AUTOSAR XML (schema 4-1-3)
standard types defined: boolean, sint8, uint16, uint32, uint8, boolean_CompuMethod, boolean_DataConstr, sint8_DataConstr, uint16_DataConstr, uint32_DataConstr, uint8_DataConstr, sint16
package /ComponentTypes
  swc implementation Implementation_HvacDampr_Ctrl: behavior=HvacDampr_Ctrl_InternalBehavior
    code-descriptors:
      code Default: artifact-descriptors=autosar-engineering-object={short-label=Default, category=SWSRC}
package /IoHwAb/Interface
  client server interface IoHwAb_IoDiagHbr
    operation Hbr_Get: possible-error=IoHwAb_IoDiagHbr/E_NOT_OK
      arg id_u16: type=ImplementationDataTypes/uint16, direction=IN, server-argument-impl-policy=USE-ARGUMENT-TYPE
      arg val_u32: type=uint32, direction=OUT, server-argument-impl-policy=USE-ARGUMENT-TYPE
    error E_NOT_OK: error-code=1
package /MICROSAR/Dem_swc/DataTypes
  5 x impl type:
    Dem_DebounceResetStatusType: compu {0=DEM_DEBOUNCE_STATUS_FREEZE, 1=DEM_DEBOUNCE_STATUS_RESET}, range raw 0..255, implementation-data-type=ImplementationDataTypes/uint8
    Dem_DTCFormatType: compu {0=DEM_DTC_FORMAT_OBD, 1=DEM_DTC_FORMAT_UDS, 2=DEM_DTC_FORMAT_J1939}, range raw 0..2, implementation-data-type=ImplementationDataTypes/uint8
    Dem_EventStatusType:
      compu {0=DEM_EVENT_STATUS_PASSED, 1=DEM_EVENT_STATUS_FAILED, 2=DEM_EVENT_STATUS_PREPASSED, 3=DEM_EVENT_STATUS_PREFAILED, 4=DEM_EVENT_STATUS_FDC_THRESHOLD_REACHED, 5=DEM_EVENT_STATUS_PASSED_CONDITIONS_NOT_FULFILLED, 6=DEM_EVENT_STATUS_FAILED_CONDITIONS_NOT_FULFILLED, 7=DEM_EVENT_STATUS_PREPASSED_CONDITIONS_NOT_FULFILLED, 8=DEM_EVENT_STATUS_PREFAILED_CONDITIONS_NOT_FULFILLED}
      range raw 0..255
      implementation-data-type=ImplementationDataTypes/uint8
    Dem_MaxDataValueType: category=ARRAY, sw-calibration-access=READ-ONLY
      element Dem_MaxDataValueTypeElement: array-size=40, array-size-semantics=FIXED-SIZE, implementation-data-type=ImplementationDataTypes/uint8
    Dem_UdsStatusByteType:
      compu {mask 1: 1=DEM_UDS_STATUS_TF (bit 0: TestFailed), mask 2: 2=DEM_UDS_STATUS_TFTOC (bit 1: TestFailedThisOperationCycle), mask 4: 4=DEM_UDS_STATUS_PDTC (bit 2: PendingDTC), mask 8: 8=DEM_UDS_STATUS_CDTC (bit 3: ConfirmedDTC), mask 16: 16=DEM_UDS_STATUS_TNCSLC (bit 4: TestNotCompletedSinceLastClear), mask 32: 32=DEM_UDS_STATUS_TFSLC (bit 5: TestFailedSinceLastClear), mask 64: 64=DEM_UDS_STATUS_TNCTOC (bit 6: TestNotCompletedThisOperationCycle), mask 128: 128=DEM_UDS_STATUS_WIR (bit 7: WarningIndicatorRequested)}
      range raw 0..255
      implementation-data-type=ImplementationDataTypes/uint8
package /MICROSAR/Dem_swc/Interfaces
  client server interface DiagnosticMonitor: is-service=true, service-kind=DIAGNOSTIC-EVENT-MANAGER
    11 x operation:
      GetDTCOfEvent: possible-error=[DEM_E_NO_DTC_AVAILABLE, DiagnosticMonitor/E_NOT_OK]
        arg DTCFormat: type=Dem_DTCFormatType, direction=IN, server-argument-impl-policy=USE-ARGUMENT-TYPE
        arg DTCOfEvent: type=uint32, direction=OUT, server-argument-impl-policy=USE-ARGUMENT-TYPE
      GetEventExtendedDataRecordEx: possible-error=[DEM_BUFFER_TOO_SMALL, DEM_NO_SUCH_ELEMENT, DiagnosticMonitor/E_NOT_OK]
        arg RecordNumber: type=ImplementationDataTypes/uint8, direction=IN, server-argument-impl-policy=USE-ARGUMENT-TYPE
        arg DestBuffer: type=Dem_MaxDataValueType, direction=OUT, server-argument-impl-policy=USE-ARGUMENT-TYPE
        arg BufSize: type=ImplementationDataTypes/uint16, direction=INOUT, server-argument-impl-policy=USE-ARGUMENT-TYPE
      GetEventFailed: possible-error=DiagnosticMonitor/E_NOT_OK
        arg EventFailed: type=ImplementationDataTypes/boolean, direction=OUT, server-argument-impl-policy=USE-ARGUMENT-TYPE
      GetEventFreezeFrameDataEx: possible-error=[DEM_BUFFER_TOO_SMALL, DEM_NO_SUCH_ELEMENT, DiagnosticMonitor/E_NOT_OK]
        4 x arg, all with server-argument-impl-policy=USE-ARGUMENT-TYPE:
          RecordNumber: type=ImplementationDataTypes/uint8, direction=IN
          DataId: type=ImplementationDataTypes/uint16, direction=IN
          DestBuffer: type=Dem_MaxDataValueType, direction=OUT
          BufSize: type=ImplementationDataTypes/uint16, direction=INOUT
      GetEventStatus: possible-error=DiagnosticMonitor/E_NOT_OK
        arg UDSStatusByte: type=Dem_UdsStatusByteType, direction=OUT, server-argument-impl-policy=USE-ARGUMENT-TYPE
      GetEventTested: possible-error=DiagnosticMonitor/E_NOT_OK
        arg EventTested: type=ImplementationDataTypes/boolean, direction=OUT, server-argument-impl-policy=USE-ARGUMENT-TYPE
      GetEventUdsStatus: possible-error=DiagnosticMonitor/E_NOT_OK
        arg UDSStatusByte: type=Dem_UdsStatusByteType, direction=OUT, server-argument-impl-policy=USE-ARGUMENT-TYPE
      GetFaultDetectionCounter: possible-error=[DEM_E_NO_FDC_AVAILABLE, DiagnosticMonitor/E_NOT_OK]
        arg FaultDetectionCounter: type=sint8, direction=OUT, server-argument-impl-policy=USE-ARGUMENT-TYPE
      ResetEventDebounceStatus: possible-error=DiagnosticMonitor/E_NOT_OK
        arg DebounceResetStatus: type=Dem_DebounceResetStatusType, direction=IN, server-argument-impl-policy=USE-ARGUMENT-TYPE
      ResetEventStatus: possible-error=DiagnosticMonitor/E_NOT_OK
      SetEventStatus: possible-error=DiagnosticMonitor/E_NOT_OK
        arg EventStatus: type=Dem_EventStatusType, direction=IN, server-argument-impl-policy=USE-ARGUMENT-TYPE
    5 x error:
      DEM_BUFFER_TOO_SMALL: error-code=21
      DEM_E_NO_DTC_AVAILABLE: error-code=10
      DEM_E_NO_FDC_AVAILABLE: error-code=14
      DEM_NO_SUCH_ELEMENT: error-code=48
      E_NOT_OK: error-code=1
package /UAES/ASW/ApplicationDataTypes
  25 x app type, all with sw-calibration-access=READ-WRITE:
    Appl_HVAC_CRCHmixToPosCnv_CUR: category=CURVE, sw-calprm-axis-set={sw-axis-index=1, category=COM_AXIS, sw-axis-individual={compu {identical}, sw-max-axis-points=2, sw-min-axis-points=2, range raw 0..255}}, compu {identical}, range raw 0..65535
    Appl_HVAC_CRCHmixToPosCnv_CUR2: category=CURVE, sw-calprm-axis-set={sw-axis-index=1, category=COM_AXIS, sw-axis-individual={compu {identical}, sw-max-axis-points=2, sw-min-axis-points=2, range raw 0..255}}, compu {identical}, range raw 0..65535
    Appl_HVAC_CRCHmixToPosCnv_CUR3: category=CURVE, sw-calprm-axis-set={sw-axis-index=1, category=COM_AXIS, sw-axis-individual={compu {identical}, sw-max-axis-points=2, sw-min-axis-points=2, range raw 0..255}}, compu {identical}, range raw 0..65535
    Appl_HVAC_CRCPosToHmixCnv_CUR: category=CURVE, sw-calprm-axis-set={sw-axis-index=1, category=COM_AXIS, sw-axis-individual={compu {identical}, sw-max-axis-points=2, sw-min-axis-points=2, range raw 0..65535}}, compu {identical}, range raw 0..255
    Appl_HVAC_CRCPosToHmixCnv_CUR2: category=CURVE, sw-calprm-axis-set={sw-axis-index=1, category=COM_AXIS, sw-axis-individual={compu {identical}, sw-max-axis-points=2, sw-min-axis-points=2, range raw 0..65535}}, compu {identical}, range raw 0..255
    Appl_HVAC_CRCPosToHmixCnv_CUR3: category=CURVE, sw-calprm-axis-set={sw-axis-index=1, category=COM_AXIS, sw-axis-individual={compu {identical}, sw-max-axis-points=2, sw-min-axis-points=2, range raw 0..65535}}, compu {identical}, range raw 0..255
    Appl_HVAC_DrTempHmixToPosCnv_CUR: category=CURVE, sw-calprm-axis-set={sw-axis-index=1, category=COM_AXIS, sw-axis-individual={compu {identical}, sw-max-axis-points=2, sw-min-axis-points=2, range raw 0..65535}}, compu {identical}, range raw 0..65535
    Appl_HVAC_DrTempHmixToPosCnv_CUR2: category=CURVE, sw-calprm-axis-set={sw-axis-index=1, category=COM_AXIS, sw-axis-individual={compu {identical}, sw-max-axis-points=2, sw-min-axis-points=2, range raw 0..65535}}, compu {identical}, range raw 0..65535
    Appl_HVAC_DrTempHmixToPosCnv_CUR3: category=CURVE, sw-calprm-axis-set={sw-axis-index=1, category=COM_AXIS, sw-axis-individual={compu {identical}, sw-max-axis-points=2, sw-min-axis-points=2, range raw 0..65535}}, compu {identical}, range raw 0..65535
    Appl_HVAC_DrTempPosToHmixCnv_CUR: category=CURVE, sw-calprm-axis-set={sw-axis-index=1, category=COM_AXIS, sw-axis-individual={compu {identical}, sw-max-axis-points=2, sw-min-axis-points=2, range raw 0..65535}}, compu {identical}, range raw 0..65535
    Appl_HVAC_DrTempPosToHmixCnv_CUR2: category=CURVE, sw-calprm-axis-set={sw-axis-index=1, category=COM_AXIS, sw-axis-individual={compu {identical}, sw-max-axis-points=2, sw-min-axis-points=2, range raw 0..65535}}, compu {identical}, range raw 0..65535
    Appl_HVAC_DrTempPosToHmixCnv_CUR3: category=CURVE, sw-calprm-axis-set={sw-axis-index=1, category=COM_AXIS, sw-axis-individual={compu {identical}, sw-max-axis-points=2, sw-min-axis-points=2, range raw 0..65535}}, compu {identical}, range raw 0..65535
    Appl_HVAC_PaTempHmixToPosCnv_CUR: category=CURVE, sw-calprm-axis-set={sw-axis-index=1, category=COM_AXIS, sw-axis-individual={compu {identical}, sw-max-axis-points=2, sw-min-axis-points=2, range raw 0..65535}}, compu {identical}, range raw 0..65535
    Appl_HVAC_PaTempHmixToPosCnv_CUR2: category=CURVE, sw-calprm-axis-set={sw-axis-index=1, category=COM_AXIS, sw-axis-individual={compu {identical}, sw-max-axis-points=2, sw-min-axis-points=2, range raw 0..65535}}, compu {identical}, range raw 0..65535
    Appl_HVAC_PaTempHmixToPosCnv_CUR3: category=CURVE, sw-calprm-axis-set={sw-axis-index=1, category=COM_AXIS, sw-axis-individual={compu {identical}, sw-max-axis-points=2, sw-min-axis-points=2, range raw 0..65535}}, compu {identical}, range raw 0..65535
    Appl_HVAC_PaTempPosToHmixCnv_CUR: category=CURVE, sw-calprm-axis-set={sw-axis-index=1, category=COM_AXIS, sw-axis-individual={compu {identical}, sw-max-axis-points=2, sw-min-axis-points=2, range raw 0..65535}}, compu {identical}, range raw 0..65535
    Appl_HVAC_PaTempPosToHmixCnv_CUR2: category=CURVE, sw-calprm-axis-set={sw-axis-index=1, category=COM_AXIS, sw-axis-individual={compu {identical}, sw-max-axis-points=2, sw-min-axis-points=2, range raw 0..65535}}, compu {identical}, range raw 0..65535
    Appl_HVAC_PaTempPosToHmixCnv_CUR3: category=CURVE, sw-calprm-axis-set={sw-axis-index=1, category=COM_AXIS, sw-axis-individual={compu {identical}, sw-max-axis-points=2, sw-min-axis-points=2, range raw 0..65535}}, compu {identical}, range raw 0..65535
    Appl_HvacDampr_ReTempHmixToPosCnv_CUR: category=CURVE, sw-calprm-axis-set={sw-axis-index=1, category=COM_AXIS, sw-axis-individual={compu {identical}, sw-max-axis-points=2, sw-min-axis-points=2, range raw 0..65535}}, compu {identical}, range raw 0..65535
    Appl_HvacDampr_ReTempHmixToPosCnv2_CUR: category=CURVE, sw-calprm-axis-set={sw-axis-index=1, category=COM_AXIS, sw-axis-individual={compu {identical}, sw-max-axis-points=2, sw-min-axis-points=2, range raw 0..65535}}, compu {identical}, range raw 0..65535
    Appl_HvacDampr_ReTempHmixToPosCnv3_CUR: category=CURVE, sw-calprm-axis-set={sw-axis-index=1, category=COM_AXIS, sw-axis-individual={compu {identical}, sw-max-axis-points=2, sw-min-axis-points=2, range raw 0..65535}}, compu {identical}, range raw 0..65535
    Appl_HvacDampr_ReTempPosToHmixCnv_CUR: category=CURVE, sw-calprm-axis-set={sw-axis-index=1, category=COM_AXIS, sw-axis-individual={compu {identical}, sw-max-axis-points=2, sw-min-axis-points=2, range raw 0..65535}}, compu {identical}, range raw 0..65535
    Appl_HvacDampr_ReTempPosToHmixCnv2_CUR: category=CURVE, sw-calprm-axis-set={sw-axis-index=1, category=COM_AXIS, sw-axis-individual={compu {identical}, sw-max-axis-points=2, sw-min-axis-points=2, range raw 0..65535}}, compu {identical}, range raw 0..65535
    Appl_HvacDampr_ReTempPosToHmixCnv3_CUR: category=CURVE, sw-calprm-axis-set={sw-axis-index=1, category=COM_AXIS, sw-axis-individual={compu {identical}, sw-max-axis-points=2, sw-min-axis-points=2, range raw 0..65535}}, compu {identical}, range raw 0..65535
    U_q1_mV_u16: category=VALUE, compu {phys=raw for raw -INF..INF; unit mV}, range phys 0..65535, raw 0..65535
package /UAES/ASW/CompuMethods
  compu method CM_boolean: 0=FALSE, 1=TRUE
package /UAES/ASW/DataConstrs
  range DC_boolean: raw 0..1
  range DC_sint16: raw -32768..32767
package /UAES/ASW/DataTypeMappingSets
  data type mapping set DTMS_HvacDampr_Ctrl
    data-type-maps:
      application-data-type=Appl_HVAC_CRCHmixToPosCnv_CUR, implementation-data-type=HVAC_CRCHmixToPosCnv_CUR_Type
      application-data-type=Appl_HVAC_CRCHmixToPosCnv_CUR2, implementation-data-type=HVAC_CRCHmixToPosCnv_CUR2_Type
      application-data-type=Appl_HVAC_CRCHmixToPosCnv_CUR3, implementation-data-type=HVAC_CRCHmixToPosCnv_CUR3_Type
      application-data-type=Appl_HVAC_CRCPosToHmixCnv_CUR, implementation-data-type=HVAC_CRCPosToHmixCnv_CUR_Type
      application-data-type=Appl_HVAC_CRCPosToHmixCnv_CUR2, implementation-data-type=HVAC_CRCPosToHmixCnv_CUR2_Type
      application-data-type=Appl_HVAC_CRCPosToHmixCnv_CUR3, implementation-data-type=HVAC_CRCPosToHmixCnv_CUR3_Type
      application-data-type=Appl_HVAC_DrTempHmixToPosCnv_CUR, implementation-data-type=HVAC_DrTempHmixToPosCnv_CUR_Type
      application-data-type=Appl_HVAC_DrTempHmixToPosCnv_CUR2, implementation-data-type=HVAC_DrTempHmixToPosCnv_CUR2_Type
      application-data-type=Appl_HVAC_DrTempHmixToPosCnv_CUR3, implementation-data-type=HVAC_DrTempHmixToPosCnv_CUR3_Type
      application-data-type=Appl_HVAC_DrTempPosToHmixCnv_CUR, implementation-data-type=HVAC_DrTempPosToHmixCnv_CUR_Type
      application-data-type=Appl_HVAC_DrTempPosToHmixCnv_CUR2, implementation-data-type=HVAC_DrTempPosToHmixCnv_CUR2_Type
      application-data-type=Appl_HVAC_DrTempPosToHmixCnv_CUR3, implementation-data-type=HVAC_DrTempPosToHmixCnv_CUR3_Type
      application-data-type=Appl_HVAC_PaTempHmixToPosCnv_CUR, implementation-data-type=HVAC_PaTempHmixToPosCnv_CUR_Type
      application-data-type=Appl_HVAC_PaTempHmixToPosCnv_CUR2, implementation-data-type=HVAC_PaTempHmixToPosCnv_CUR2_Type
      application-data-type=Appl_HVAC_PaTempHmixToPosCnv_CUR3, implementation-data-type=HVAC_PaTempHmixToPosCnv_CUR3_Type
      application-data-type=Appl_HVAC_PaTempPosToHmixCnv_CUR, implementation-data-type=HVAC_PaTempPosToHmixCnv_CUR_Type
      application-data-type=Appl_HVAC_PaTempPosToHmixCnv_CUR2, implementation-data-type=HVAC_PaTempPosToHmixCnv_CUR2_Type
      application-data-type=Appl_HVAC_PaTempPosToHmixCnv_CUR3, implementation-data-type=HVAC_PaTempPosToHmixCnv_CUR3_Type
      application-data-type=Appl_HvacDampr_ReTempHmixToPosCnv_CUR, implementation-data-type=HvacDampr_ReTempHmixToPosCnv_CUR_Type
      application-data-type=Appl_HvacDampr_ReTempHmixToPosCnv2_CUR, implementation-data-type=HvacDampr_ReTempHmixToPosCnv2_CUR_Type
      application-data-type=Appl_HvacDampr_ReTempHmixToPosCnv3_CUR, implementation-data-type=HvacDampr_ReTempHmixToPosCnv3_CUR_Type
      application-data-type=Appl_HvacDampr_ReTempPosToHmixCnv_CUR, implementation-data-type=HvacDampr_ReTempPosToHmixCnv_CUR_Type
      application-data-type=Appl_HvacDampr_ReTempPosToHmixCnv2_CUR, implementation-data-type=HvacDampr_ReTempPosToHmixCnv2_CUR_Type
      application-data-type=Appl_HvacDampr_ReTempPosToHmixCnv3_CUR, implementation-data-type=HvacDampr_ReTempPosToHmixCnv3_CUR_Type
      application-data-type=U_q1_mV_u16, implementation-data-type=ImplementationDataTypes/uint16
package /UAES/ASW/ImplementationDataTypes
  26 x impl type:
    HVAC_CRCHmixToPosCnv_CUR_Type: category=STRUCTURE
      element N1: implementation-data-type=ImplementationDataTypes/uint8
      element BP1: implementation-data-type=rt_Array_uint8_2
      element Table: implementation-data-type=rt_Array_uint16_2
    HVAC_CRCHmixToPosCnv_CUR2_Type: category=STRUCTURE
      element N1: implementation-data-type=ImplementationDataTypes/uint8
      element BP1: implementation-data-type=rt_Array_uint8_2
      element Table: implementation-data-type=rt_Array_uint16_2
    HVAC_CRCHmixToPosCnv_CUR3_Type: category=STRUCTURE
      element N1: implementation-data-type=ImplementationDataTypes/uint8
      element BP1: implementation-data-type=rt_Array_uint8_2
      element Table: implementation-data-type=rt_Array_uint16_2
    HVAC_CRCPosToHmixCnv_CUR_Type: category=STRUCTURE
      element N1: implementation-data-type=ImplementationDataTypes/uint16
      element BP1: implementation-data-type=rt_Array_uint16_2
      element Table: implementation-data-type=rt_Array_uint8_2
    HVAC_CRCPosToHmixCnv_CUR2_Type: category=STRUCTURE
      element N1: implementation-data-type=ImplementationDataTypes/uint16
      element BP1: implementation-data-type=rt_Array_uint16_2
      element Table: implementation-data-type=rt_Array_uint8_2
    HVAC_CRCPosToHmixCnv_CUR3_Type: category=STRUCTURE
      element N1: implementation-data-type=ImplementationDataTypes/uint16
      element BP1: implementation-data-type=rt_Array_uint16_2
      element Table: implementation-data-type=rt_Array_uint8_2
    HVAC_DrTempHmixToPosCnv_CUR_Type: category=STRUCTURE
      element N1: implementation-data-type=ImplementationDataTypes/uint16
      element BP1: implementation-data-type=rt_Array_uint16_2
      element Table: implementation-data-type=rt_Array_uint16_2
    HVAC_DrTempHmixToPosCnv_CUR2_Type: category=STRUCTURE
      element N1: implementation-data-type=ImplementationDataTypes/uint16
      element BP1: implementation-data-type=rt_Array_uint16_2
      element Table: implementation-data-type=rt_Array_uint16_2
    HVAC_DrTempHmixToPosCnv_CUR3_Type: category=STRUCTURE
      element N1: implementation-data-type=ImplementationDataTypes/uint16
      element BP1: implementation-data-type=rt_Array_uint16_2
      element Table: implementation-data-type=rt_Array_uint16_2
    HVAC_DrTempPosToHmixCnv_CUR_Type: category=STRUCTURE
      element N1: implementation-data-type=ImplementationDataTypes/uint16
      element BP1: implementation-data-type=rt_Array_uint16_2
      element Table: implementation-data-type=rt_Array_uint16_2
    HVAC_DrTempPosToHmixCnv_CUR2_Type: category=STRUCTURE
      element N1: implementation-data-type=ImplementationDataTypes/uint16
      element BP1: implementation-data-type=rt_Array_uint16_2
      element Table: implementation-data-type=rt_Array_uint16_2
    HVAC_DrTempPosToHmixCnv_CUR3_Type: category=STRUCTURE
      element N1: implementation-data-type=ImplementationDataTypes/uint16
      element BP1: implementation-data-type=rt_Array_uint16_2
      element Table: implementation-data-type=rt_Array_uint16_2
    HVAC_PaTempHmixToPosCnv_CUR_Type: category=STRUCTURE
      element N1: implementation-data-type=ImplementationDataTypes/uint16
      element BP1: implementation-data-type=rt_Array_uint16_2
      element Table: implementation-data-type=rt_Array_uint16_2
    HVAC_PaTempHmixToPosCnv_CUR2_Type: category=STRUCTURE
      element N1: implementation-data-type=ImplementationDataTypes/uint16
      element BP1: implementation-data-type=rt_Array_uint16_2
      element Table: implementation-data-type=rt_Array_uint16_2
    HVAC_PaTempHmixToPosCnv_CUR3_Type: category=STRUCTURE
      element N1: implementation-data-type=ImplementationDataTypes/uint16
      element BP1: implementation-data-type=rt_Array_uint16_2
      element Table: implementation-data-type=rt_Array_uint16_2
    HVAC_PaTempPosToHmixCnv_CUR_Type: category=STRUCTURE
      element N1: implementation-data-type=ImplementationDataTypes/uint16
      element BP1: implementation-data-type=rt_Array_uint16_2
      element Table: implementation-data-type=rt_Array_uint16_2
    HVAC_PaTempPosToHmixCnv_CUR2_Type: category=STRUCTURE
      element N1: implementation-data-type=ImplementationDataTypes/uint16
      element BP1: implementation-data-type=rt_Array_uint16_2
      element Table: implementation-data-type=rt_Array_uint16_2
    HVAC_PaTempPosToHmixCnv_CUR3_Type: category=STRUCTURE
      element N1: implementation-data-type=ImplementationDataTypes/uint16
      element BP1: implementation-data-type=rt_Array_uint16_2
      element Table: implementation-data-type=rt_Array_uint16_2
    HvacDampr_ReTempHmixToPosCnv_CUR_Type: category=STRUCTURE
      element N1: implementation-data-type=ImplementationDataTypes/uint16
      element BP1: implementation-data-type=rt_Array_uint16_2
      element Table: implementation-data-type=rt_Array_uint16_2
    HvacDampr_ReTempHmixToPosCnv2_CUR_Type: category=STRUCTURE
      element N1: implementation-data-type=ImplementationDataTypes/uint16
      element BP1: implementation-data-type=rt_Array_uint16_2
      element Table: implementation-data-type=rt_Array_uint16_2
    HvacDampr_ReTempHmixToPosCnv3_CUR_Type: category=STRUCTURE
      element N1: implementation-data-type=ImplementationDataTypes/uint16
      element BP1: implementation-data-type=rt_Array_uint16_2
      element Table: implementation-data-type=rt_Array_uint16_2
    HvacDampr_ReTempPosToHmixCnv_CUR_Type: category=STRUCTURE
      element N1: implementation-data-type=ImplementationDataTypes/uint16
      element BP1: implementation-data-type=rt_Array_uint16_2
      element Table: implementation-data-type=rt_Array_uint16_2
    HvacDampr_ReTempPosToHmixCnv2_CUR_Type: category=STRUCTURE
      element N1: implementation-data-type=ImplementationDataTypes/uint16
      element BP1: implementation-data-type=rt_Array_uint16_2
      element Table: implementation-data-type=rt_Array_uint16_2
    HvacDampr_ReTempPosToHmixCnv3_CUR_Type: category=STRUCTURE
      element N1: implementation-data-type=ImplementationDataTypes/uint16
      element BP1: implementation-data-type=rt_Array_uint16_2
      element Table: implementation-data-type=rt_Array_uint16_2
    rt_Array_uint16_2: category=ARRAY
      element rt_Array_uint16_2: array-size=2, array-size-semantics=FIXED-SIZE, implementation-data-type=ImplementationDataTypes/uint16
    rt_Array_uint8_2: category=ARRAY
      element rt_Array_uint8_2: array-size=2, array-size-semantics=FIXED-SIZE, implementation-data-type=ImplementationDataTypes/uint8
package /UAES/ASW/ImplementationDataTypes/Ground
  139 x constant specification:
    CAN_CRC_2LAYER_FLOW_VAL: value-spec=CAN_CRC_2LAYER_FLOW_VAL:250
    CIRCUIT_FAULT_JUDEG_TIME: value-spec=CIRCUIT_FAULT_JUDEG_TIME:400
    CIRCUIT_NORMAL: value-spec=CIRCUIT_NORMAL:0
    CIRCUIT_SHORT_GND: value-spec=CIRCUIT_SHORT_GND:1
    CIRCUIT_SHORT_GND_VAL: value-spec=CIRCUIT_SHORT_GND_VAL:68
    CIRCUIT_SHORT_POWER: value-spec=CIRCUIT_SHORT_POWER:2
    CIRCUIT_SHORT_POWER_VAL: value-spec=CIRCUIT_SHORT_POWER_VAL:4930
    DCMOTOR_JAM: value-spec=DCMOTOR_JAM:3
    DCMOTOR_MODE_BACK_TICKS: value-spec=DCMOTOR_MODE_BACK_TICKS:2
    DCMOTOR_MODE_DEFMAX_POS: value-spec=DCMOTOR_MODE_DEFMAX_POS:4930
    DCMOTOR_MODE_FACEMIX_POS: value-spec=DCMOTOR_MODE_FACEMIX_POS:68
    DCMOTOR_MODE_POS_DIFF: value-spec=DCMOTOR_MODE_POS_DIFF:100
    DCMOTOR_MODE_POS_LIMIT: value-spec=DCMOTOR_MODE_POS_LIMIT:400
    DCMOTOR_MODE_STALL_TICKS: value-spec=DCMOTOR_MODE_STALL_TICKS:1600
    DCMOTOR_MODE_STOP_TICKS: value-spec=DCMOTOR_MODE_STOP_TICKS:1
    DCMOTOR_NORMAL: value-spec=DCMOTOR_NORMAL:0
    DCMOTOR_POS_UNREACHED: value-spec=DCMOTOR_POS_UNREACHED:4
    HVAC_CRCHmixToPosCnv_CUR: value-spec=fields=[N:2, X:[0, 100], Y:[3100, 2500]]
    HVAC_CRCHmixToPosCnv_CUR2: value-spec=fields=[N:2, X:[0, 100], Y:[500, 4500]]
    HVAC_CRCHmixToPosCnv_CUR3: value-spec=fields=[N:2, X:[0, 100], Y:[890, 4110]]
    HVAC_CRCPosToHmixCnv_CUR: value-spec=fields=[N:2, X:[2500, 3100], Y:[100, 0]]
    HVAC_CRCPosToHmixCnv_CUR2: value-spec=fields=[N:2, X:[500, 4500], Y:[0, 100]]
    HVAC_CRCPosToHmixCnv_CUR3: value-spec=fields=[N:2, X:[890, 4110], Y:[0, 100]]
    HVAC_DrTempHmixToPosCnv_CUR: value-spec=fields=[N:2, X:[0, 1000], Y:[3560, 890]]
    HVAC_DrTempHmixToPosCnv_CUR2: value-spec=fields=[N:2, X:[0, 1000], Y:[500, 4500]]
    HVAC_DrTempHmixToPosCnv_CUR3: value-spec=fields=[N:2, X:[0, 1000], Y:[4500, 500]]
    HVAC_DrTempPosToHmixCnv_CUR: value-spec=fields=[N:2, X:[890, 3560], Y:[1000, 0]]
    HVAC_DrTempPosToHmixCnv_CUR2: value-spec=fields=[N:2, X:[500, 4500], Y:[0, 1000]]
    HVAC_DrTempPosToHmixCnv_CUR3: value-spec=fields=[N:2, X:[500, 4500], Y:[1000, 0]]
    HVAC_PaTempHmixToPosCnv_CUR: value-spec=fields=[N:2, X:[0, 1000], Y:[1440, 4110]]
    HVAC_PaTempHmixToPosCnv_CUR2: value-spec=fields=[N:2, X:[0, 1000], Y:[500, 4500]]
    HVAC_PaTempHmixToPosCnv_CUR3: value-spec=fields=[N:2, X:[0, 1000], Y:[4500, 500]]
    HVAC_PaTempPosToHmixCnv_CUR: value-spec=fields=[N:2, X:[1440, 4110], Y:[0, 1000]]
    HVAC_PaTempPosToHmixCnv_CUR2: value-spec=fields=[N:2, X:[500, 4500], Y:[0, 1000]]
    HVAC_PaTempPosToHmixCnv_CUR3: value-spec=fields=[N:2, X:[500, 4500], Y:[1000, 0]]
    HvacDampr_ReTempHmixToPosCnv_CUR: value-spec=fields=[N:2, X:[0, 1000], Y:[900, 4100]]
    HvacDampr_ReTempHmixToPosCnv2_CUR: value-spec=fields=[N:2, X:[0, 1000], Y:[500, 4500]]
    HvacDampr_ReTempHmixToPosCnv3_CUR: value-spec=fields=[N:2, X:[0, 1000], Y:[4500, 500]]
    HvacDampr_ReTempPosToHmixCnv_CUR: value-spec=fields=[N:2, X:[900, 4100], Y:[0, 1000]]
    HvacDampr_ReTempPosToHmixCnv2_CUR: value-spec=fields=[N:2, X:[500, 4500], Y:[0, 1000]]
    HvacDampr_ReTempPosToHmixCnv3_CUR: value-spec=fields=[N:2, X:[500, 4500], Y:[1000, 0]]
    MDD_CRC_2LAYER_FLOW_SPEC_1: value-spec=MDD_CRC_2LAYER_FLOW_SPEC_1:1900
    MDD_CRC_2LAYER_FLOW_SPEC_2: value-spec=MDD_CRC_2LAYER_FLOW_SPEC_2:2500
    MDD_DEF_POSITION_SPEC_1: value-spec=MDD_DEF_POSITION_SPEC_1:900
    MDD_DEF_POSITION_SPEC_2: value-spec=MDD_DEF_POSITION_SPEC_2:4500
    MDD_DEF_POSITION_SPEC_3: value-spec=MDD_DEF_POSITION_SPEC_3:609
    MDD_FLR_POSITION_SPEC_1: value-spec=MDD_FLR_POSITION_SPEC_1:2570
    MDD_FLR_POSITION_SPEC_2: value-spec=MDD_FLR_POSITION_SPEC_2:2500
    MDD_FLR_POSITION_SPEC_3: value-spec=MDD_FLR_POSITION_SPEC_3:2441
    MDD_FLRDEF_POSITION_SPEC_1: value-spec=MDD_FLRDEF_POSITION_SPEC_1:2030
    MDD_FLRDEF_POSITION_SPEC_2: value-spec=MDD_FLRDEF_POSITION_SPEC_2:3470
    MDD_FLRDEF_POSITION_SPEC_3: value-spec=MDD_FLRDEF_POSITION_SPEC_3:1545
    MDD_PNL_POSITION_SPEC_1: value-spec=MDD_PNL_POSITION_SPEC_1:4100
    MDD_PNL_POSITION_SPEC_2: value-spec=MDD_PNL_POSITION_SPEC_2:500
    MDD_PNL_POSITION_SPEC_3: value-spec=MDD_PNL_POSITION_SPEC_3:4271
    MDD_PNL_VAL: value-spec=MDD_PNL_VAL:1
    MDD_PNLFLR_POSITION_SPEC_1: value-spec=MDD_PNLFLR_POSITION_SPEC_1:3300
    MDD_PNLFLR_POSITION_SPEC_2: value-spec=MDD_PNLFLR_POSITION_SPEC_2:1530
    MDD_PNLFLR_POSITION_SPEC_3: value-spec=MDD_PNLFLR_POSITION_SPEC_3:3336
    MDD_RE_FLR_POSITION_SPEC_1: value-spec=3850
    MDD_RE_PNL_POSITION_SPEC_1: value-spec=1380
    MDD_RE_PNLFLR_POSITION_SPEC_1: value-spec=2615
    MDD_RE_ST1_POSITION_SPEC_1: value-spec=1380
    MDD_RE_ST1_VAL_SPEC1: value-spec=MDD_ST1_VAL_SPEC1:1
    MDD_RE_ST2_POSITION_SPEC_1: value-spec=2615
    MDD_RE_ST2_VAL_SPEC1: value-spec=MDD_ST2_VAL_SPEC1:2
    MDD_RE_ST3_POSITION_SPEC_1: value-spec=3850
    MDD_RE_ST3_VAL_SPEC1: value-spec=MDD_ST3_VAL_SPEC1:3
    MDD_ST_RE_DIFF_POSITION: value-spec=MDD_ST_RE_DIFF_POSITION:100
    MDD_ST1_POSITION_SPEC_1: value-spec=MDD_ST1_POSITION_SPEC_1:900
    MDD_ST1_POSITION_SPEC_2: value-spec=MDD_ST1_POSITION_SPEC_2:500
    MDD_ST1_POSITION_SPEC_3: value-spec=MDD_ST1_POSITION_SPEC_3:629
    MDD_ST1_VAL_SPEC1: value-spec=MDD_ST1_VAL_SPEC1:5
    MDD_ST1_VAL_SPEC2: value-spec=MDD_ST1_VAL_SPEC2:1
    MDD_ST1_VAL_SPEC3: value-spec=MDD_ST1_VAL_SPEC3:5
    MDD_ST2_POSITION_SPEC_1: value-spec=MDD_ST2_POSITION_SPEC_1:2030
    MDD_ST2_POSITION_SPEC_2: value-spec=MDD_ST2_POSITION_SPEC_2:1530
    MDD_ST2_POSITION_SPEC_3: value-spec=MDD_ST2_POSITION_SPEC_3:1545
    MDD_ST2_VAL_SPEC1: value-spec=MDD_ST2_VAL_SPEC1:4
    MDD_ST2_VAL_SPEC2: value-spec=MDD_ST2_VAL_SPEC2:2
    MDD_ST2_VAL_SPEC3: value-spec=MDD_ST2_VAL_SPEC3:4
    MDD_ST3_POSITION_SPEC_1: value-spec=MDD_ST3_POSITION_SPEC_1:2570
    MDD_ST3_POSITION_SPEC_2: value-spec=MDD_ST3_POSITION_SPEC_2:2500
    MDD_ST3_POSITION_SPEC_3: value-spec=MDD_ST3_POSITION_SPEC_3:2441
    MDD_ST3_VAL_SPEC{1..3}: value-spec=MDD_ST3_VAL_SPEC{1..3}:3
    MDD_ST4_POSITION_SPEC_1: value-spec=MDD_ST4_POSITION_SPEC_1:3300
    MDD_ST4_POSITION_SPEC_2: value-spec=MDD_ST4_POSITION_SPEC_2:3470
    MDD_ST4_POSITION_SPEC_3: value-spec=MDD_ST4_POSITION_SPEC_3:3336
    MDD_ST4_VAL_SPEC1: value-spec=MDD_ST4_VAL_SPEC1:2
    MDD_ST4_VAL_SPEC2: value-spec=MDD_ST4_VAL_SPEC2:4
    MDD_ST4_VAL_SPEC3: value-spec=MDD_ST4_VAL_SPEC3:2
    MDD_ST5_POSITION_SPEC_1: value-spec=MDD_ST5_POSITION_SPEC_1:4100
    MDD_ST5_POSITION_SPEC_2: value-spec=MDD_ST5_POSITION_SPEC_2:4500
    MDD_ST5_POSITION_SPEC_3: value-spec=MDD_ST5_POSITION_SPEC_3:4271
    MDD_ST5_VAL_SPEC1: value-spec=MDD_ST5_VAL_SPEC1:1
    MDD_ST5_VAL_SPEC2: value-spec=MDD_ST5_VAL_SPEC2:5
    MDD_ST5_VAL_SPEC3: value-spec=MDD_ST5_VAL_SPEC3:1
    MOTO_CRC_SPECT1_P_TURN: value-spec=MOTO_CRC_SPECT1_P_TURN:2
    MOTO_CRC_SPECT1_R_TURN: value-spec=MOTO_CRC_SPECT1_R_TURN:1
    MOTO_CRC_SPECT2_P_TURN: value-spec=MOTO_CRC_SPECT2_P_TURN:1
    MOTO_CRC_SPECT2_R_TURN: value-spec=MOTO_CRC_SPECT2_R_TURN:2
    MOTO_CRC_SPECT3_P_TURN: value-spec=MOTO_CRC_SPECT3_P_TURN:1
    MOTO_CRC_SPECT3_R_TURN: value-spec=MOTO_CRC_SPECT3_R_TURN:2
    MOTO_DR_TEMP_SPECT1_P_TURN: value-spec=MOTO_DR_TEMP_SPECT1_P_TURN:2
    MOTO_DR_TEMP_SPECT1_R_TURN: value-spec=MOTO_DR_TEMP_SPECT1_R_TURN:1
    MOTO_DR_TEMP_SPECT2_P_TURN: value-spec=MOTO_DR_TEMP_SPECT2_P_TURN:1
    MOTO_DR_TEMP_SPECT2_R_TURN: value-spec=MOTO_DR_TEMP_SPECT2_R_TURN:2
    MOTO_DR_TEMP_SPECT3_P_TURN: value-spec=MOTO_DR_TEMP_SPECT3_P_TURN:2
    MOTO_DR_TEMP_SPECT3_R_TURN: value-spec=MOTO_DR_TEMP_SPECT3_R_TURN:2
    MOTO_FALSE_JUDGE_VAL: value-spec=MOTO_FALSE_JUDGE_VAL:80
    MOTO_INIT_DEAL_TIME: value-spec=3
    MOTO_MODE_SPECT1_P_TURN: value-spec=MOTO_MODE_SPECT1_P_TURN:2
    MOTO_MODE_SPECT1_R_TURN: value-spec=MOTO_MODE_SPECT1_R_TURN:1
    MOTO_MODE_SPECT2_P_TURN: value-spec=MOTO_MODE_SPECT2_P_TURN:1
    MOTO_MODE_SPECT2_R_TURN: value-spec=MOTO_MODE_SPECT2_R_TURN:2
    MOTO_MODE_SPECT3_P_TURN: value-spec=MOTO_MODE_SPECT3_P_TURN:2
    MOTO_MODE_SPECT3_R_TURN: value-spec=MOTO_MODE_SPECT3_R_TURN:1
    MOTO_PA_TEMP_SPECT1_P_TURN: value-spec=MOTO_PA_TEMP_SPECT1_P_TURN:1
    MOTO_PA_TEMP_SPECT1_R_TURN: value-spec=MOTO_PA_TEMP_SPECT1_R_TURN:2
    MOTO_PA_TEMP_SPECT2_P_TURN: value-spec=MOTO_PA_TEMP_SPECT2_P_TURN:1
    MOTO_PA_TEMP_SPECT2_R_TURN: value-spec=MOTO_PA_TEMP_SPECT2_R_TURN:2
    MOTO_PA_TEMP_SPECT3_P_TURN: value-spec=MOTO_PA_TEMP_SPECT3_P_TURN:2
    MOTO_PA_TEMP_SPECT3_R_TURN: value-spec=MOTO_PA_TEMP_SPECT3_R_TURN:1
    MOTO_RE_TEMP_SPECT1_P_TURN: value-spec=MOTO_PA_TEMP_SPECT1_P_TURN:1
    MOTO_RE_TEMP_SPECT1_R_TURN: value-spec=MOTO_PA_TEMP_SPECT1_R_TURN:2
    MOTO_RE_TEMP_SPECT2_P_TURN: value-spec=MOTO_PA_TEMP_SPECT2_P_TURN:1
    MOTO_RE_TEMP_SPECT2_R_TURN: value-spec=MOTO_PA_TEMP_SPECT2_R_TURN:2
    MOTO_RE_TEMP_SPECT3_P_TURN: value-spec=MOTO_PA_TEMP_SPECT3_P_TURN:2
    MOTO_RE_TEMP_SPECT3_R_TURN: value-spec=MOTO_PA_TEMP_SPECT3_R_TURN:1
    MOTO_REMODE_SPECT1_P_TURN: value-spec=MOTO_MODE_SPECT2_P_TURN:1
    MOTO_REMODE_SPECT1_R_TURN: value-spec=MOTO_MODE_SPECT2_R_TURN:2
    MOTO_RUNNING: value-spec=MOTO_RUNNING:1
    MOTO_STOP: value-spec=MOTO_STOP:0
    MOTO_STOP_RUNNING: value-spec=MOTO_STOP_RUNNING:0
    PRM_A02_CFG_SPEC_VAL: value-spec=PRM_A02_CFG_SPEC_VAL:0
    PRM_A08_CFG_SPEC_VAL: value-spec=PRM_A08_CFG_SPEC_VAL:2
    PRM_A29_CFG_SPEC_VAL: value-spec=PRM_A29_CFG_SPEC_VAL:1
package /UAES/ASW/PortInterfaces
  client server interface IoHwAb_HbrModCtrl
    operation Hbr_SetMod: possible-error=IoHwAb_HbrModCtrl/E_NOT_OK
      arg id_u16: type=ImplementationDataTypes/uint16, direction=IN, server-argument-impl-policy=USE-ARGUMENT-TYPE
      arg mod_u8: type=ImplementationDataTypes/uint8, direction=IN, server-argument-impl-policy=USE-ARGUMENT-TYPE
    error E_NOT_OK: error-code=1
  client server interface IoHwAb_IoSigAdc
    operation Adc_Get: possible-error=IoHwAb_IoSigAdc/E_NOT_OK
      arg id_u16: type=ImplementationDataTypes/uint16, direction=IN, server-argument-impl-policy=USE-ARGUMENT-TYPE
      arg val_s16: type=sint16, direction=OUT, server-argument-impl-policy=USE-ARGUMENT-TYPE
    operation AdcFac_Get: possible-error=IoHwAb_IoSigAdc/E_NOT_OK
      arg id_u16: type=ImplementationDataTypes/uint16, direction=IN, server-argument-impl-policy=USE-ARGUMENT-TYPE
      arg val_s16: type=sint16, direction=OUT, server-argument-impl-policy=USE-ARGUMENT-TYPE
    operation AdcVRMBatt_Get: possible-error=IoHwAb_IoSigAdc/E_NOT_OK
      arg id_u16: type=ImplementationDataTypes/uint16, direction=IN, server-argument-impl-policy=USE-ARGUMENT-TYPE
      arg val_u8: type=ImplementationDataTypes/uint8, direction=OUT, server-argument-impl-policy=USE-ARGUMENT-TYPE
    error E_NOT_OK: error-code=1
  73 x sender receiver interface:
    gCFG_u8ReHVACBoxTyp: invalidation-policy{data-element=gCFG_u8ReHVACBoxTyp/Val, handle-invalid=DONT-INVALIDATE}
      data Val: sw-calibration-access=READ-ONLY, type=ImplementationDataTypes/uint8
    gPRM_bHotpumpCfg: invalidation-policy{data-element=gPRM_bHotpumpCfg/Val, handle-invalid=DONT-INVALIDATE}
      data Val: sw-calibration-access=READ-ONLY, type=ImplementationDataTypes/boolean
    gPRM_u8AirConditionBoxSpecCfg: invalidation-policy{data-element=gPRM_u8AirConditionBoxSpecCfg/Val, handle-invalid=DONT-INVALIDATE}
      data Val: type=ImplementationDataTypes/uint8
    gPRM_u8ReAirConditionBoxSpecCfg: invalidation-policy{data-element=gPRM_u8ReAirConditionBoxSpecCfg/Val, handle-invalid=DONT-INVALIDATE}
      data Val: sw-calibration-access=READ-ONLY, type=ImplementationDataTypes/uint8
    gPRM_u8VehicleTypeCfg: invalidation-policy{data-element=gPRM_u8VehicleTypeCfg/Val, handle-invalid=DONT-INVALIDATE}
      data Val: sw-calibration-access=READ-ONLY, range raw 0..255, type=ImplementationDataTypes/uint8
    HvacDampr_bReqVldDrvrMixMot: invalidation-policy{data-element=HvacDampr_bReqVldDrvrMixMot/Val, handle-invalid=DONT-INVALIDATE}
      data Val: sw-calibration-access=READ-ONLY, type=ImplementationDataTypes/boolean
    HvacDampr_bReqVldDrvrRcrltnMot: invalidation-policy{data-element=HvacDampr_bReqVldDrvrRcrltnMot/Val, handle-invalid=DONT-INVALIDATE}
      data Val: sw-calibration-access=READ-ONLY, type=ImplementationDataTypes/boolean
    HvacDampr_bReqVldMotMot: invalidation-policy{data-element=HvacDampr_bReqVldMotMot/Val, handle-invalid=DONT-INVALIDATE}
      data Val: sw-calibration-access=READ-ONLY, type=ImplementationDataTypes/boolean
    HvacDampr_bReqVldPassMixMot: invalidation-policy{data-element=HvacDampr_bReqVldPassMixMot/Val, handle-invalid=DONT-INVALIDATE}
      data Val: sw-calibration-access=READ-ONLY, type=ImplementationDataTypes/boolean
    HvacDampr_bReqVldPassRcrltnMot: invalidation-policy{data-element=HvacDampr_bReqVldPassRcrltnMot/Val, handle-invalid=DONT-INVALIDATE}
      data Val: sw-calibration-access=READ-ONLY, type=ImplementationDataTypes/boolean
    HvacDampr_bReqVldRcrltnMot: invalidation-policy{data-element=HvacDampr_bReqVldRcrltnMot/Val, handle-invalid=DONT-INVALIDATE}
      data Val: sw-calibration-access=READ-ONLY, type=ImplementationDataTypes/boolean
    HvacDampr_bReqVldReMixMot: invalidation-policy{data-element=HvacDampr_bReqVldReMixMot/Val, handle-invalid=DONT-INVALIDATE}
      data Val: sw-calibration-access=READ-ONLY, type=ImplementationDataTypes/boolean
    HvacDampr_bReqVldReMotMot: invalidation-policy{data-element=HvacDampr_bReqVldReMotMot/Val, handle-invalid=DONT-INVALIDATE}
      data Val: sw-calibration-access=READ-ONLY, type=ImplementationDataTypes/boolean
    HvacDampr_bUdsTrigDrvrRcrltnMot: invalidation-policy{data-element=HvacDampr_bUdsTrigDrvrRcrltnMot/Val, handle-invalid=DONT-INVALIDATE}
      data Val: sw-calibration-access=READ-ONLY, type=ImplementationDataTypes/boolean
    HvacDampr_bUdsTrigModMot: invalidation-policy{data-element=HvacDampr_bUdsTrigModMot/Val, handle-invalid=DONT-INVALIDATE}
      data Val: sw-calibration-access=READ-ONLY, type=ImplementationDataTypes/boolean
    HvacDampr_bUdsTrigPassMixMot: invalidation-policy{data-element=HvacDampr_bUdsTrigPassMixMot/Val, handle-invalid=DONT-INVALIDATE}
      data Val: sw-calibration-access=READ-ONLY, type=ImplementationDataTypes/boolean
    HvacDampr_bUdsTrigPassRcrltnMot: invalidation-policy{data-element=HvacDampr_bUdsTrigPassRcrltnMot/Val, handle-invalid=DONT-INVALIDATE}
      data Val: sw-calibration-access=READ-ONLY, type=ImplementationDataTypes/boolean
    HvacDampr_bUdsTrigPsgrMixMot: invalidation-policy{data-element=HvacDampr_bUdsTrigPsgrMixMot/Val, handle-invalid=DONT-INVALIDATE}
      data Val: sw-calibration-access=READ-ONLY, type=ImplementationDataTypes/boolean
    HvacDampr_bUdsTrigRcrltnMot: invalidation-policy{data-element=HvacDampr_bUdsTrigRcrltnMot/Val, handle-invalid=DONT-INVALIDATE}
      data Val: sw-calibration-access=READ-ONLY, type=ImplementationDataTypes/boolean
    HvacDampr_stDrvrMixMotAct: invalidation-policy{data-element=HvacDampr_stDrvrMixMotAct/Val, handle-invalid=DONT-INVALIDATE}
      data Val: sw-calibration-access=READ-ONLY, type=ImplementationDataTypes/uint8
    HvacDampr_stDrvrMixMotDir: invalidation-policy{data-element=HvacDampr_stDrvrMixMotDir/Val, handle-invalid=DONT-INVALIDATE}
      data Val: sw-calibration-access=READ-ONLY, type=ImplementationDataTypes/uint8
    HvacDampr_stDrvrMixMotFlt: invalidation-policy{data-element=HvacDampr_stDrvrMixMotFlt/Val, handle-invalid=DONT-INVALIDATE}
      data Val: sw-calibration-access=READ-ONLY, type=ImplementationDataTypes/uint8
    HvacDampr_stDrvrMixMotRunng: invalidation-policy{data-element=HvacDampr_stDrvrMixMotRunng/Val, handle-invalid=DONT-INVALIDATE}
      data Val: sw-calibration-access=READ-ONLY, type=ImplementationDataTypes/uint8
    HvacDampr_stDrvrRcrltnMotAct: invalidation-policy{data-element=HvacDampr_stDrvrRcrltnMotAct/Val, handle-invalid=DONT-INVALIDATE}
      data Val: sw-calibration-access=READ-ONLY, type=ImplementationDataTypes/uint8
    HvacDampr_stDrvrRcrltnMotDir: invalidation-policy{data-element=HvacDampr_stDrvrRcrltnMotDir/Val, handle-invalid=DONT-INVALIDATE}
      data Val: sw-calibration-access=READ-ONLY, type=ImplementationDataTypes/uint8
    HvacDampr_stDrvrRcrltnMotFlt: invalidation-policy{data-element=HvacDampr_stDrvrRcrltnMotFlt/Val, handle-invalid=DONT-INVALIDATE}
      data Val: sw-calibration-access=READ-ONLY, type=ImplementationDataTypes/uint8
    HvacDampr_stDrvrRcrltnMotRunng: invalidation-policy{data-element=HvacDampr_stDrvrRcrltnMotRunng/Val, handle-invalid=DONT-INVALIDATE}
      data Val: sw-calibration-access=READ-ONLY, type=ImplementationDataTypes/uint8
    HvacDampr_stModMotAct: invalidation-policy{data-element=HvacDampr_stModMotAct/Val, handle-invalid=DONT-INVALIDATE}
      data Val: sw-calibration-access=READ-ONLY, type=ImplementationDataTypes/uint8
    HvacDampr_stModMotDir: invalidation-policy{data-element=HvacDampr_stModMotDir/Val, handle-invalid=DONT-INVALIDATE}
      data Val: sw-calibration-access=READ-ONLY, type=ImplementationDataTypes/uint8
    HvacDampr_stModMotFlt: invalidation-policy{data-element=HvacDampr_stModMotFlt/Val, handle-invalid=DONT-INVALIDATE}
      data Val: sw-calibration-access=READ-ONLY, type=ImplementationDataTypes/uint8
    HvacDampr_stModMotRunng: invalidation-policy{data-element=HvacDampr_stModMotRunng/Val, handle-invalid=DONT-INVALIDATE}
      data Val: sw-calibration-access=READ-ONLY, type=ImplementationDataTypes/uint8
    HvacDampr_stPassMixMotAct: invalidation-policy{data-element=HvacDampr_stPassMixMotAct/Val, handle-invalid=DONT-INVALIDATE}
      data Val: sw-calibration-access=READ-ONLY, type=ImplementationDataTypes/uint8
    HvacDampr_stPassMixMotDir: invalidation-policy{data-element=HvacDampr_stPassMixMotDir/Val, handle-invalid=DONT-INVALIDATE}
      data Val: sw-calibration-access=READ-ONLY, type=ImplementationDataTypes/uint8
    HvacDampr_stPassMixMotFlt: invalidation-policy{data-element=HvacDampr_stPassMixMotFlt/Val, handle-invalid=DONT-INVALIDATE}
      data Val: sw-calibration-access=READ-ONLY, type=ImplementationDataTypes/uint8
    HvacDampr_stPassMixMotRunng: invalidation-policy{data-element=HvacDampr_stPassMixMotRunng/Val, handle-invalid=DONT-INVALIDATE}
      data Val: sw-calibration-access=READ-ONLY, type=ImplementationDataTypes/uint8
    HvacDampr_stPassRcrltnMotAct: invalidation-policy{data-element=HvacDampr_stPassRcrltnMotAct/Val, handle-invalid=DONT-INVALIDATE}
      data Val: sw-calibration-access=READ-ONLY, type=ImplementationDataTypes/uint8
    HvacDampr_stPassRcrltnMotDir: invalidation-policy{data-element=HvacDampr_stPassRcrltnMotDir/Val, handle-invalid=DONT-INVALIDATE}
      data Val: sw-calibration-access=READ-ONLY, type=ImplementationDataTypes/uint8
    HvacDampr_stPassRcrltnMotFlt: invalidation-policy{data-element=HvacDampr_stPassRcrltnMotFlt/Val, handle-invalid=DONT-INVALIDATE}
      data Val: sw-calibration-access=READ-ONLY, type=ImplementationDataTypes/uint8
    HvacDampr_stPassRcrltnMotRunng: invalidation-policy{data-element=HvacDampr_stPassRcrltnMotRunng/Val, handle-invalid=DONT-INVALIDATE}
      data Val: sw-calibration-access=READ-ONLY, type=ImplementationDataTypes/uint8
    HvacDampr_stRcrltnMotAct: invalidation-policy{data-element=HvacDampr_stRcrltnMotAct/Val, handle-invalid=DONT-INVALIDATE}
      data Val: sw-calibration-access=READ-ONLY, type=ImplementationDataTypes/uint8
    HvacDampr_stRcrltnMotDir: invalidation-policy{data-element=HvacDampr_stRcrltnMotDir/Val, handle-invalid=DONT-INVALIDATE}
      data Val: sw-calibration-access=READ-ONLY, type=ImplementationDataTypes/uint8
    HvacDampr_stRcrltnMotFlt: invalidation-policy{data-element=HvacDampr_stRcrltnMotFlt/Val, handle-invalid=DONT-INVALIDATE}
      data Val: sw-calibration-access=READ-ONLY, type=ImplementationDataTypes/uint8
    HvacDampr_stRcrltnMotRunng: invalidation-policy{data-element=HvacDampr_stRcrltnMotRunng/Val, handle-invalid=DONT-INVALIDATE}
      data Val: sw-calibration-access=READ-ONLY, type=ImplementationDataTypes/uint8
    HvacDampr_stReMixMotAct: invalidation-policy{data-element=HvacDampr_stReMixMotAct/Val, handle-invalid=DONT-INVALIDATE}
      data Val: sw-calibration-access=READ-ONLY, type=ImplementationDataTypes/uint8
    HvacDampr_stReMixMotDir: invalidation-policy{data-element=HvacDampr_stReMixMotDir/Val, handle-invalid=DONT-INVALIDATE}
      data Val: sw-calibration-access=READ-ONLY, type=ImplementationDataTypes/uint8
    HvacDampr_stReMixMotFlt: invalidation-policy{data-element=HvacDampr_stReMixMotFlt/Val, handle-invalid=DONT-INVALIDATE}
      data Val: sw-calibration-access=READ-ONLY, type=ImplementationDataTypes/uint8
    HvacDampr_stReMixMotRunng: invalidation-policy{data-element=HvacDampr_stReMixMotRunng/Val, handle-invalid=DONT-INVALIDATE}
      data Val: sw-calibration-access=READ-ONLY, type=ImplementationDataTypes/uint8
    HvacDampr_stReModMotAct: invalidation-policy{data-element=HvacDampr_stReModMotAct/Val, handle-invalid=DONT-INVALIDATE}
      data Val: sw-calibration-access=READ-ONLY, type=ImplementationDataTypes/uint8
    HvacDampr_stReModMotDir: invalidation-policy{data-element=HvacDampr_stReModMotDir/Val, handle-invalid=DONT-INVALIDATE}
      data Val: sw-calibration-access=READ-ONLY, type=ImplementationDataTypes/uint8
    HvacDampr_stReModMotFlt: invalidation-policy{data-element=HvacDampr_stReModMotFlt/Val, handle-invalid=DONT-INVALIDATE}
      data Val: sw-calibration-access=READ-ONLY, type=ImplementationDataTypes/uint8
    HvacDampr_stReModMotRunng: invalidation-policy{data-element=HvacDampr_stReModMotRunng/Val, handle-invalid=DONT-INVALIDATE}
      data Val: sw-calibration-access=READ-ONLY, type=ImplementationDataTypes/uint8
    HvacDampr_stReqDrvrMixMot: invalidation-policy{data-element=HvacDampr_stReqDrvrMixMot/Val, handle-invalid=DONT-INVALIDATE}
      data Val: sw-calibration-access=READ-ONLY, type=ImplementationDataTypes/uint8
    HvacDampr_stReqDrvrRcrltnMot: invalidation-policy{data-element=HvacDampr_stReqDrvrRcrltnMot/Val, handle-invalid=DONT-INVALIDATE}
      data Val: sw-calibration-access=READ-ONLY, type=ImplementationDataTypes/uint8
    HvacDampr_stReqMotMot: invalidation-policy{data-element=HvacDampr_stReqMotMot/Val, handle-invalid=DONT-INVALIDATE}
      data Val: sw-calibration-access=READ-ONLY, type=ImplementationDataTypes/uint8
    HvacDampr_stReqPassMixMot: invalidation-policy{data-element=HvacDampr_stReqPassMixMot/Val, handle-invalid=DONT-INVALIDATE}
      data Val: sw-calibration-access=READ-ONLY, type=ImplementationDataTypes/uint8
    HvacDampr_stReqPassRcrltnMot: invalidation-policy{data-element=HvacDampr_stReqPassRcrltnMot/Val, handle-invalid=DONT-INVALIDATE}
      data Val: sw-calibration-access=READ-ONLY, type=ImplementationDataTypes/uint8
    HvacDampr_stReqRcrltnMot: invalidation-policy{data-element=HvacDampr_stReqRcrltnMot/Val, handle-invalid=DONT-INVALIDATE}
      data Val: sw-calibration-access=READ-ONLY, type=ImplementationDataTypes/uint8
    HvacDampr_stReqReMixMot: invalidation-policy{data-element=HvacDampr_stReqReMixMot/Val, handle-invalid=DONT-INVALIDATE}
      data Val: sw-calibration-access=READ-ONLY, type=ImplementationDataTypes/uint8
    HvacDampr_stReqReMotMot: invalidation-policy{data-element=HvacDampr_stReqReMotMot/Val, handle-invalid=DONT-INVALIDATE}
      data Val: sw-calibration-access=READ-ONLY, type=ImplementationDataTypes/uint8
    HvacDampr_stReqUdsDrvrRcrltnMot: invalidation-policy{data-element=HvacDampr_stReqUdsDrvrRcrltnMot/Val, handle-invalid=DONT-INVALIDATE}
      data Val: sw-calibration-access=READ-ONLY, type=ImplementationDataTypes/uint8
    HvacDampr_stReqUdsModMot: invalidation-policy{data-element=HvacDampr_stReqUdsModMot/Val, handle-invalid=DONT-INVALIDATE}
      data Val: sw-calibration-access=READ-ONLY, type=ImplementationDataTypes/uint8
    HvacDampr_stReqUdsPassMixMot: invalidation-policy{data-element=HvacDampr_stReqUdsPassMixMot/Val, handle-invalid=DONT-INVALIDATE}
      data Val: sw-calibration-access=READ-ONLY, type=ImplementationDataTypes/uint8
    HvacDampr_stReqUdsPassRcrltnMot: invalidation-policy{data-element=HvacDampr_stReqUdsPassRcrltnMot/Val, handle-invalid=DONT-INVALIDATE}
      data Val: sw-calibration-access=READ-ONLY, type=ImplementationDataTypes/uint8
    HvacDampr_stReqUdsPsgrMixMot: invalidation-policy{data-element=HvacDampr_stReqUdsPsgrMixMot/Val, handle-invalid=DONT-INVALIDATE}
      data Val: sw-calibration-access=READ-ONLY, type=ImplementationDataTypes/uint8
    HvacDampr_stReqUdsRcrltnMot: invalidation-policy{data-element=HvacDampr_stReqUdsRcrltnMot/Val, handle-invalid=DONT-INVALIDATE}
      data Val: sw-calibration-access=READ-ONLY, type=ImplementationDataTypes/uint8
    HvacDampr_uDrvrMixMotFb: invalidation-policy{data-element=HvacDampr_uDrvrMixMotFb/Val, handle-invalid=DONT-INVALIDATE}
      data Val: sw-calibration-access=READ-ONLY, type=ImplementationDataTypes/uint16
    HvacDampr_uDrvrRcrltnMotFb: invalidation-policy{data-element=HvacDampr_uDrvrRcrltnMotFb/Val, handle-invalid=DONT-INVALIDATE}
      data Val: sw-calibration-access=READ-ONLY, type=ImplementationDataTypes/uint16
    HvacDampr_uModMotFb: invalidation-policy{data-element=HvacDampr_uModMotFb/Val, handle-invalid=DONT-INVALIDATE}
      data Val: sw-calibration-access=READ-ONLY, type=ImplementationDataTypes/uint16
    HvacDampr_uPassMixMotFb: invalidation-policy{data-element=HvacDampr_uPassMixMotFb/Val, handle-invalid=DONT-INVALIDATE}
      data Val: sw-calibration-access=READ-ONLY, type=ImplementationDataTypes/uint16
    HvacDampr_uPassRcrltnMotFb: invalidation-policy{data-element=HvacDampr_uPassRcrltnMotFb/Val, handle-invalid=DONT-INVALIDATE}
      data Val: sw-calibration-access=READ-ONLY, type=ImplementationDataTypes/uint16
    HvacDampr_uRcrltnMotFb: invalidation-policy{data-element=HvacDampr_uRcrltnMotFb/Val, handle-invalid=DONT-INVALIDATE}
      data Val: sw-calibration-access=READ-ONLY, type=ImplementationDataTypes/uint16
    HvacDampr_uReMixMotFb: invalidation-policy{data-element=HvacDampr_uReMixMotFb/Val, handle-invalid=DONT-INVALIDATE}
      data Val: sw-calibration-access=READ-ONLY, type=ImplementationDataTypes/uint16
    HvacDampr_uReModMotFb: invalidation-policy{data-element=HvacDampr_uReModMotFb/Val, handle-invalid=DONT-INVALIDATE}
      data Val: sw-calibration-access=READ-ONLY, type=ImplementationDataTypes/uint16
package /UAES/ASW/SwAddrMethods
  sw addr method CALDATA
package /UAES/ASW/SwComponentTypes
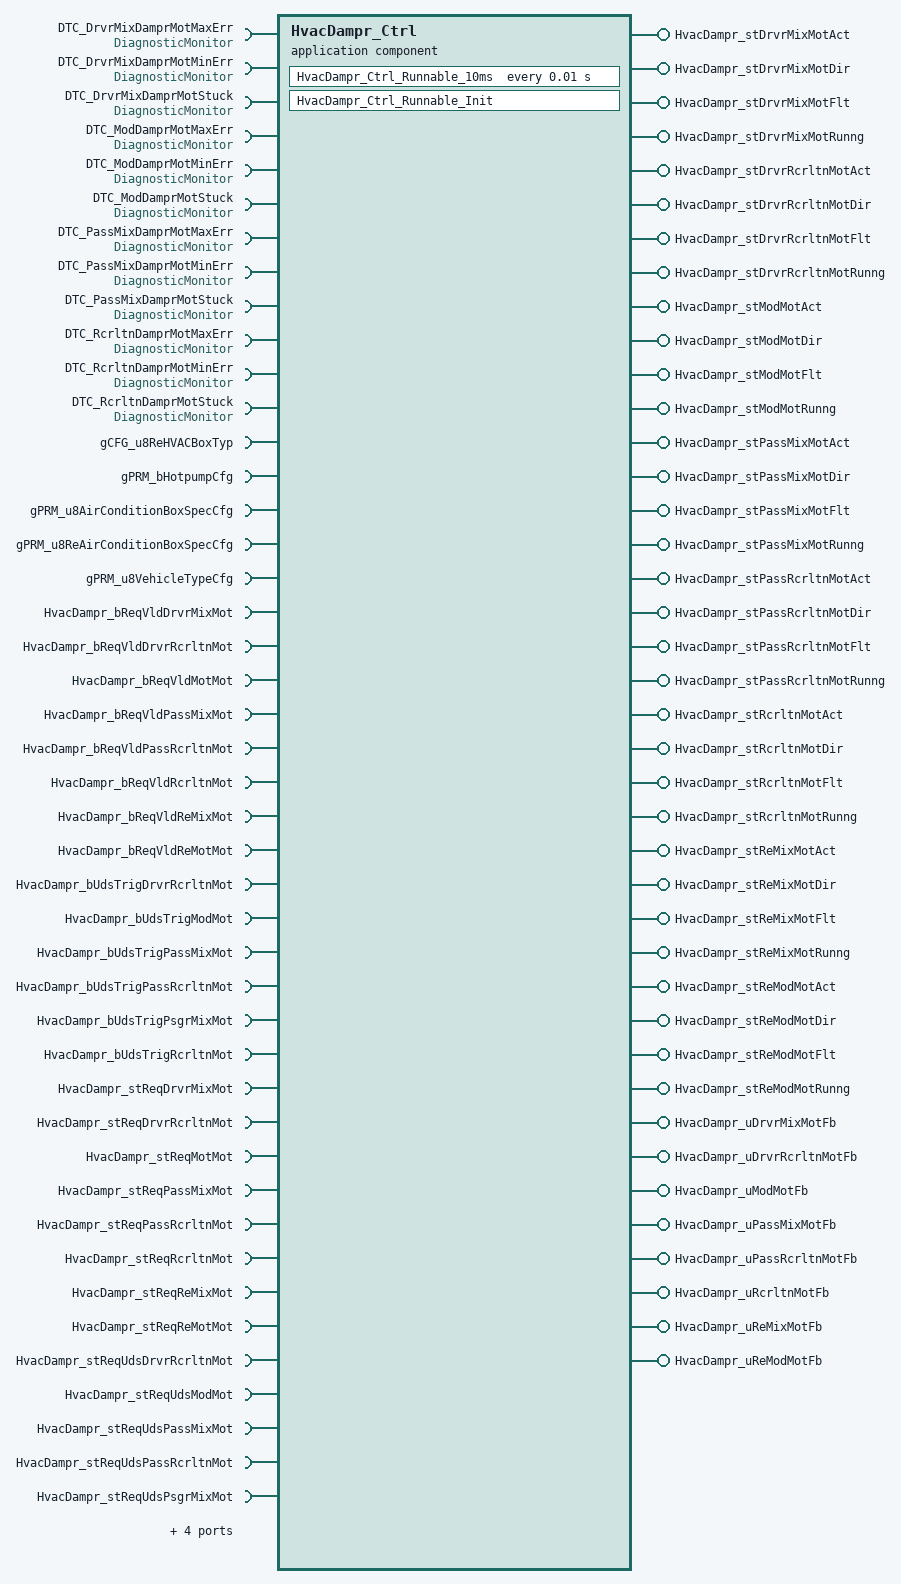
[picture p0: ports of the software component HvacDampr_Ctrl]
  application sw component type HvacDampr_Ctrl
    40 x provide port:
      HvacDampr_stDrvrMixMotAct: nonqueued-sender-com-spec{data-element=HvacDampr_stDrvrMixMotAct/Val, init-value=0}, provided-interface=HvacDampr_stDrvrMixMotAct
      HvacDampr_stDrvrMixMotDir: nonqueued-sender-com-spec{data-element=HvacDampr_stDrvrMixMotDir/Val, init-value=0}, provided-interface=HvacDampr_stDrvrMixMotDir
      HvacDampr_stDrvrMixMotFlt: nonqueued-sender-com-spec{data-element=HvacDampr_stDrvrMixMotFlt/Val, init-value=0}, provided-interface=HvacDampr_stDrvrMixMotFlt
      HvacDampr_stDrvrMixMotRunng: nonqueued-sender-com-spec{data-element=HvacDampr_stDrvrMixMotRunng/Val, init-value=0}, provided-interface=HvacDampr_stDrvrMixMotRunng
      HvacDampr_stDrvrRcrltnMotAct: nonqueued-sender-com-spec{data-element=HvacDampr_stDrvrRcrltnMotAct/Val, init-value=0}, provided-interface=HvacDampr_stDrvrRcrltnMotAct
      HvacDampr_stDrvrRcrltnMotDir: nonqueued-sender-com-spec{data-element=HvacDampr_stDrvrRcrltnMotDir/Val, init-value=0}, provided-interface=HvacDampr_stDrvrRcrltnMotDir
      HvacDampr_stDrvrRcrltnMotFlt: nonqueued-sender-com-spec{data-element=HvacDampr_stDrvrRcrltnMotFlt/Val, init-value=0}, provided-interface=HvacDampr_stDrvrRcrltnMotFlt
      HvacDampr_stDrvrRcrltnMotRunng: nonqueued-sender-com-spec{data-element=HvacDampr_stDrvrRcrltnMotRunng/Val, init-value=0}, provided-interface=HvacDampr_stDrvrRcrltnMotRunng
      HvacDampr_stModMotAct: nonqueued-sender-com-spec{data-element=HvacDampr_stModMotAct/Val, init-value=0}, provided-interface=HvacDampr_stModMotAct
      HvacDampr_stModMotDir: nonqueued-sender-com-spec{data-element=HvacDampr_stModMotDir/Val, init-value=0}, provided-interface=HvacDampr_stModMotDir
      HvacDampr_stModMotFlt: nonqueued-sender-com-spec{data-element=HvacDampr_stModMotFlt/Val, init-value=0}, provided-interface=HvacDampr_stModMotFlt
      HvacDampr_stModMotRunng: nonqueued-sender-com-spec{data-element=HvacDampr_stModMotRunng/Val, init-value=0}, provided-interface=HvacDampr_stModMotRunng
      HvacDampr_stPassMixMotAct: nonqueued-sender-com-spec{data-element=HvacDampr_stPassMixMotAct/Val, init-value=0}, provided-interface=HvacDampr_stPassMixMotAct
      HvacDampr_stPassMixMotDir: nonqueued-sender-com-spec{data-element=HvacDampr_stPassMixMotDir/Val, init-value=0}, provided-interface=HvacDampr_stPassMixMotDir
      HvacDampr_stPassMixMotFlt: nonqueued-sender-com-spec{data-element=HvacDampr_stPassMixMotFlt/Val, init-value=0}, provided-interface=HvacDampr_stPassMixMotFlt
      HvacDampr_stPassMixMotRunng: nonqueued-sender-com-spec{data-element=HvacDampr_stPassMixMotRunng/Val, init-value=0}, provided-interface=HvacDampr_stPassMixMotRunng
      HvacDampr_stPassRcrltnMotAct: nonqueued-sender-com-spec{data-element=HvacDampr_stPassRcrltnMotAct/Val, init-value=0}, provided-interface=HvacDampr_stPassRcrltnMotAct
      HvacDampr_stPassRcrltnMotDir: nonqueued-sender-com-spec{data-element=HvacDampr_stPassRcrltnMotDir/Val, init-value=0}, provided-interface=HvacDampr_stPassRcrltnMotDir
      HvacDampr_stPassRcrltnMotFlt: nonqueued-sender-com-spec{data-element=HvacDampr_stPassRcrltnMotFlt/Val, init-value=0}, provided-interface=HvacDampr_stPassRcrltnMotFlt
      HvacDampr_stPassRcrltnMotRunng: nonqueued-sender-com-spec{data-element=HvacDampr_stPassRcrltnMotRunng/Val, init-value=0}, provided-interface=HvacDampr_stPassRcrltnMotRunng
      HvacDampr_stRcrltnMotAct: nonqueued-sender-com-spec{data-element=HvacDampr_stRcrltnMotAct/Val, init-value=0}, provided-interface=HvacDampr_stRcrltnMotAct
      HvacDampr_stRcrltnMotDir: nonqueued-sender-com-spec{data-element=HvacDampr_stRcrltnMotDir/Val, init-value=0}, provided-interface=HvacDampr_stRcrltnMotDir
      HvacDampr_stRcrltnMotFlt: nonqueued-sender-com-spec{data-element=HvacDampr_stRcrltnMotFlt/Val, init-value=0}, provided-interface=HvacDampr_stRcrltnMotFlt
      HvacDampr_stRcrltnMotRunng: nonqueued-sender-com-spec{data-element=HvacDampr_stRcrltnMotRunng/Val, init-value=0}, provided-interface=HvacDampr_stRcrltnMotRunng
      HvacDampr_stReMixMotAct: nonqueued-sender-com-spec{data-element=HvacDampr_stReMixMotAct/Val, init-value=0}, provided-interface=HvacDampr_stReMixMotAct
      HvacDampr_stReMixMotDir: nonqueued-sender-com-spec{data-element=HvacDampr_stReMixMotDir/Val, init-value=0}, provided-interface=HvacDampr_stReMixMotDir
      HvacDampr_stReMixMotFlt: nonqueued-sender-com-spec{data-element=HvacDampr_stReMixMotFlt/Val, init-value=0}, provided-interface=HvacDampr_stReMixMotFlt
      HvacDampr_stReMixMotRunng: nonqueued-sender-com-spec{data-element=HvacDampr_stReMixMotRunng/Val, init-value=0}, provided-interface=HvacDampr_stReMixMotRunng
      HvacDampr_stReModMotAct: nonqueued-sender-com-spec{data-element=HvacDampr_stReModMotAct/Val, init-value=0}, provided-interface=HvacDampr_stReModMotAct
      HvacDampr_stReModMotDir: nonqueued-sender-com-spec{data-element=HvacDampr_stReModMotDir/Val, init-value=0}, provided-interface=HvacDampr_stReModMotDir
      HvacDampr_stReModMotFlt: nonqueued-sender-com-spec{data-element=HvacDampr_stReModMotFlt/Val, init-value=0}, provided-interface=HvacDampr_stReModMotFlt
      HvacDampr_stReModMotRunng: nonqueued-sender-com-spec{data-element=HvacDampr_stReModMotRunng/Val, init-value=0}, provided-interface=HvacDampr_stReModMotRunng
      HvacDampr_uDrvrMixMotFb: nonqueued-sender-com-spec{data-element=HvacDampr_uDrvrMixMotFb/Val, init-value=0}, provided-interface=HvacDampr_uDrvrMixMotFb
      HvacDampr_uDrvrRcrltnMotFb: nonqueued-sender-com-spec{data-element=HvacDampr_uDrvrRcrltnMotFb/Val, init-value=0}, provided-interface=HvacDampr_uDrvrRcrltnMotFb
      HvacDampr_uModMotFb: nonqueued-sender-com-spec{data-element=HvacDampr_uModMotFb/Val, init-value=0}, provided-interface=HvacDampr_uModMotFb
      HvacDampr_uPassMixMotFb: nonqueued-sender-com-spec{data-element=HvacDampr_uPassMixMotFb/Val, init-value=0}, provided-interface=HvacDampr_uPassMixMotFb
      HvacDampr_uPassRcrltnMotFb: nonqueued-sender-com-spec{data-element=HvacDampr_uPassRcrltnMotFb/Val, init-value=0}, provided-interface=HvacDampr_uPassRcrltnMotFb
      HvacDampr_uRcrltnMotFb: nonqueued-sender-com-spec{data-element=HvacDampr_uRcrltnMotFb/Val, init-value=0}, provided-interface=HvacDampr_uRcrltnMotFb
      HvacDampr_uReMixMotFb: nonqueued-sender-com-spec{data-element=HvacDampr_uReMixMotFb/Val, init-value=0}, provided-interface=HvacDampr_uReMixMotFb
      HvacDampr_uReModMotFb: nonqueued-sender-com-spec{data-element=HvacDampr_uReModMotFb/Val, init-value=0}, provided-interface=HvacDampr_uReModMotFb
    48 x require port:
      DTC_DrvrMixDamprMotMaxErr: required-interface=DiagnosticMonitor
        required-com-specs:
          GetDTCOfEvent
          GetEventExtendedDataRecordEx
          GetEventFailed
          GetEventFreezeFrameDataEx
          GetEventStatus
          GetEventTested
          GetEventUdsStatus
          GetFaultDetectionCounter
          ResetEventDebounceStatus
          ResetEventStatus
          SetEventStatus
      DTC_DrvrMixDamprMotMinErr: required-interface=DiagnosticMonitor
        required-com-specs:
          GetDTCOfEvent
          GetEventExtendedDataRecordEx
          GetEventFailed
          GetEventFreezeFrameDataEx
          GetEventStatus
          GetEventTested
          GetEventUdsStatus
          GetFaultDetectionCounter
          ResetEventDebounceStatus
          ResetEventStatus
          SetEventStatus
      DTC_DrvrMixDamprMotStuck: required-interface=DiagnosticMonitor
        required-com-specs:
          GetDTCOfEvent
          GetEventExtendedDataRecordEx
          GetEventFailed
          GetEventFreezeFrameDataEx
          GetEventStatus
          GetEventTested
          GetEventUdsStatus
          GetFaultDetectionCounter
          ResetEventDebounceStatus
          ResetEventStatus
          SetEventStatus
      DTC_ModDamprMotMaxErr: required-interface=DiagnosticMonitor
        required-com-specs:
          GetDTCOfEvent
          GetEventExtendedDataRecordEx
          GetEventFailed
          GetEventFreezeFrameDataEx
          GetEventStatus
          GetEventTested
          GetEventUdsStatus
          GetFaultDetectionCounter
          ResetEventDebounceStatus
          ResetEventStatus
          SetEventStatus
      DTC_ModDamprMotMinErr: required-interface=DiagnosticMonitor
        required-com-specs:
          GetDTCOfEvent
          GetEventExtendedDataRecordEx
          GetEventFailed
          GetEventFreezeFrameDataEx
          GetEventStatus
          GetEventTested
          GetEventUdsStatus
          GetFaultDetectionCounter
          ResetEventDebounceStatus
          ResetEventStatus
          SetEventStatus
      DTC_ModDamprMotStuck: required-interface=DiagnosticMonitor
        required-com-specs:
          GetDTCOfEvent
          GetEventExtendedDataRecordEx
          GetEventFailed
          GetEventFreezeFrameDataEx
          GetEventStatus
          GetEventTested
          GetEventUdsStatus
          GetFaultDetectionCounter
          ResetEventDebounceStatus
          ResetEventStatus
          SetEventStatus
      DTC_PassMixDamprMotMaxErr: required-interface=DiagnosticMonitor
        required-com-specs:
          GetDTCOfEvent
          GetEventExtendedDataRecordEx
          GetEventFailed
          GetEventFreezeFrameDataEx
          GetEventStatus
          GetEventTested
          GetEventUdsStatus
          GetFaultDetectionCounter
          ResetEventDebounceStatus
          ResetEventStatus
          SetEventStatus
      DTC_PassMixDamprMotMinErr: required-interface=DiagnosticMonitor
        required-com-specs:
          GetDTCOfEvent
          GetEventExtendedDataRecordEx
          GetEventFailed
          GetEventFreezeFrameDataEx
          GetEventStatus
          GetEventTested
          GetEventUdsStatus
          GetFaultDetectionCounter
          ResetEventDebounceStatus
          ResetEventStatus
          SetEventStatus
      DTC_PassMixDamprMotStuck: required-interface=DiagnosticMonitor
        required-com-specs:
          GetDTCOfEvent
          GetEventExtendedDataRecordEx
          GetEventFailed
          GetEventFreezeFrameDataEx
          GetEventStatus
          GetEventTested
          GetEventUdsStatus
          GetFaultDetectionCounter
          ResetEventDebounceStatus
          ResetEventStatus
          SetEventStatus
      DTC_RcrltnDamprMotMaxErr: required-interface=DiagnosticMonitor
        required-com-specs:
          GetDTCOfEvent
          GetEventExtendedDataRecordEx
          GetEventFailed
          GetEventFreezeFrameDataEx
          GetEventStatus
          GetEventTested
          GetEventUdsStatus
          GetFaultDetectionCounter
          ResetEventDebounceStatus
          ResetEventStatus
          SetEventStatus
      DTC_RcrltnDamprMotMinErr: required-interface=DiagnosticMonitor
        required-com-specs:
          GetDTCOfEvent
          GetEventExtendedDataRecordEx
          GetEventFailed
          GetEventFreezeFrameDataEx
          GetEventStatus
          GetEventTested
          GetEventUdsStatus
          GetFaultDetectionCounter
          ResetEventDebounceStatus
          ResetEventStatus
          SetEventStatus
      DTC_RcrltnDamprMotStuck: required-interface=DiagnosticMonitor
        required-com-specs:
          GetDTCOfEvent
          GetEventExtendedDataRecordEx
          GetEventFailed
          GetEventFreezeFrameDataEx
          GetEventStatus
          GetEventTested
          GetEventUdsStatus
          GetFaultDetectionCounter
          ResetEventDebounceStatus
          ResetEventStatus
          SetEventStatus
      gCFG_u8ReHVACBoxTyp: nonqueued-receiver-com-spec{data-element=gCFG_u8ReHVACBoxTyp/Val, filter=data-filter-type=ALWAYS, init-value=0}, required-interface=gCFG_u8ReHVACBoxTyp
      gPRM_bHotpumpCfg: nonqueued-receiver-com-spec{data-element=gPRM_bHotpumpCfg/Val, filter=data-filter-type=ALWAYS, init-value=0}, required-interface=gPRM_bHotpumpCfg
      gPRM_u8AirConditionBoxSpecCfg: nonqueued-receiver-com-spec{data-element=gPRM_u8AirConditionBoxSpecCfg/Val, filter=data-filter-type=ALWAYS, init-value=0}, required-interface=gPRM_u8AirConditionBoxSpecCfg
      gPRM_u8ReAirConditionBoxSpecCfg: nonqueued-receiver-com-spec{data-element=gPRM_u8ReAirConditionBoxSpecCfg/Val, filter=data-filter-type=ALWAYS, init-value=0}, required-interface=gPRM_u8ReAirConditionBoxSpecCfg
      gPRM_u8VehicleTypeCfg: nonqueued-receiver-com-spec{data-element=gPRM_u8VehicleTypeCfg/Val, filter=data-filter-type=ALWAYS, init-value=0}, required-interface=gPRM_u8VehicleTypeCfg
      HvacDampr_bReqVldDrvrMixMot: nonqueued-receiver-com-spec{data-element=HvacDampr_bReqVldDrvrMixMot/Val, filter=data-filter-type=ALWAYS, init-value=0}, required-interface=HvacDampr_bReqVldDrvrMixMot
      HvacDampr_bReqVldDrvrRcrltnMot: nonqueued-receiver-com-spec{data-element=HvacDampr_bReqVldDrvrRcrltnMot/Val, filter=data-filter-type=ALWAYS, init-value=0}, required-interface=HvacDampr_bReqVldDrvrRcrltnMot
      HvacDampr_bReqVldMotMot: nonqueued-receiver-com-spec{data-element=HvacDampr_bReqVldMotMot/Val, filter=data-filter-type=ALWAYS, init-value=0}, required-interface=HvacDampr_bReqVldMotMot
      HvacDampr_bReqVldPassMixMot: nonqueued-receiver-com-spec{data-element=HvacDampr_bReqVldPassMixMot/Val, filter=data-filter-type=ALWAYS, init-value=0}, required-interface=HvacDampr_bReqVldPassMixMot
      HvacDampr_bReqVldPassRcrltnMot: nonqueued-receiver-com-spec{data-element=HvacDampr_bReqVldPassRcrltnMot/Val, filter=data-filter-type=ALWAYS, init-value=0}, required-interface=HvacDampr_bReqVldPassRcrltnMot
      HvacDampr_bReqVldRcrltnMot: nonqueued-receiver-com-spec{data-element=HvacDampr_bReqVldRcrltnMot/Val, filter=data-filter-type=ALWAYS, init-value=0}, required-interface=HvacDampr_bReqVldRcrltnMot
      HvacDampr_bReqVldReMixMot: nonqueued-receiver-com-spec{data-element=HvacDampr_bReqVldReMixMot/Val, filter=data-filter-type=ALWAYS, init-value=0}, required-interface=HvacDampr_bReqVldReMixMot
      HvacDampr_bReqVldReMotMot: nonqueued-receiver-com-spec{data-element=HvacDampr_bReqVldReMotMot/Val, filter=data-filter-type=ALWAYS, init-value=0}, required-interface=HvacDampr_bReqVldReMotMot
      HvacDampr_bUdsTrigDrvrRcrltnMot: nonqueued-receiver-com-spec{data-element=HvacDampr_bUdsTrigDrvrRcrltnMot/Val, filter=data-filter-type=ALWAYS, init-value=0}, required-interface=HvacDampr_bUdsTrigDrvrRcrltnMot
      HvacDampr_bUdsTrigModMot: nonqueued-receiver-com-spec{data-element=HvacDampr_bUdsTrigModMot/Val, filter=data-filter-type=ALWAYS, init-value=0}, required-interface=HvacDampr_bUdsTrigModMot
      HvacDampr_bUdsTrigPassMixMot: nonqueued-receiver-com-spec{data-element=HvacDampr_bUdsTrigPassMixMot/Val, filter=data-filter-type=ALWAYS, init-value=0}, required-interface=HvacDampr_bUdsTrigPassMixMot
      HvacDampr_bUdsTrigPassRcrltnMot: nonqueued-receiver-com-spec{data-element=HvacDampr_bUdsTrigPassRcrltnMot/Val, filter=data-filter-type=ALWAYS, init-value=0}, required-interface=HvacDampr_bUdsTrigPassRcrltnMot
      HvacDampr_bUdsTrigPsgrMixMot: nonqueued-receiver-com-spec{data-element=HvacDampr_bUdsTrigPsgrMixMot/Val, filter=data-filter-type=ALWAYS, init-value=0}, required-interface=HvacDampr_bUdsTrigPsgrMixMot
      HvacDampr_bUdsTrigRcrltnMot: nonqueued-receiver-com-spec{data-element=HvacDampr_bUdsTrigRcrltnMot/Val, filter=data-filter-type=ALWAYS, init-value=0}, required-interface=HvacDampr_bUdsTrigRcrltnMot
      HvacDampr_stReqDrvrMixMot: nonqueued-receiver-com-spec{data-element=HvacDampr_stReqDrvrMixMot/Val, filter=data-filter-type=ALWAYS, init-value=0}, required-interface=HvacDampr_stReqDrvrMixMot
      HvacDampr_stReqDrvrRcrltnMot: nonqueued-receiver-com-spec{data-element=HvacDampr_stReqDrvrRcrltnMot/Val, filter=data-filter-type=ALWAYS, init-value=0}, required-interface=HvacDampr_stReqDrvrRcrltnMot
      HvacDampr_stReqMotMot: nonqueued-receiver-com-spec{data-element=HvacDampr_stReqMotMot/Val, filter=data-filter-type=ALWAYS, init-value=0}, required-interface=HvacDampr_stReqMotMot
      HvacDampr_stReqPassMixMot: nonqueued-receiver-com-spec{data-element=HvacDampr_stReqPassMixMot/Val, filter=data-filter-type=ALWAYS, init-value=0}, required-interface=HvacDampr_stReqPassMixMot
      HvacDampr_stReqPassRcrltnMot: nonqueued-receiver-com-spec{data-element=HvacDampr_stReqPassRcrltnMot/Val, filter=data-filter-type=ALWAYS, init-value=0}, required-interface=HvacDampr_stReqPassRcrltnMot
      HvacDampr_stReqRcrltnMot: nonqueued-receiver-com-spec{data-element=HvacDampr_stReqRcrltnMot/Val, filter=data-filter-type=ALWAYS, init-value=0}, required-interface=HvacDampr_stReqRcrltnMot
      HvacDampr_stReqReMixMot: nonqueued-receiver-com-spec{data-element=HvacDampr_stReqReMixMot/Val, filter=data-filter-type=ALWAYS, init-value=0}, required-interface=HvacDampr_stReqReMixMot
      HvacDampr_stReqReMotMot: nonqueued-receiver-com-spec{data-element=HvacDampr_stReqReMotMot/Val, filter=data-filter-type=ALWAYS, init-value=0}, required-interface=HvacDampr_stReqReMotMot
      HvacDampr_stReqUdsDrvrRcrltnMot: nonqueued-receiver-com-spec{data-element=HvacDampr_stReqUdsDrvrRcrltnMot/Val, filter=data-filter-type=ALWAYS, init-value=0}, required-interface=HvacDampr_stReqUdsDrvrRcrltnMot
      HvacDampr_stReqUdsModMot: nonqueued-receiver-com-spec{data-element=HvacDampr_stReqUdsModMot/Val, filter=data-filter-type=ALWAYS, init-value=0}, required-interface=HvacDampr_stReqUdsModMot
      HvacDampr_stReqUdsPassMixMot: nonqueued-receiver-com-spec{data-element=HvacDampr_stReqUdsPassMixMot/Val, filter=data-filter-type=ALWAYS, init-value=0}, required-interface=HvacDampr_stReqUdsPassMixMot
      HvacDampr_stReqUdsPassRcrltnMot: nonqueued-receiver-com-spec{data-element=HvacDampr_stReqUdsPassRcrltnMot/Val, filter=data-filter-type=ALWAYS, init-value=0}, required-interface=HvacDampr_stReqUdsPassRcrltnMot
      HvacDampr_stReqUdsPsgrMixMot: nonqueued-receiver-com-spec{data-element=HvacDampr_stReqUdsPsgrMixMot/Val, filter=data-filter-type=ALWAYS, init-value=0}, required-interface=HvacDampr_stReqUdsPsgrMixMot
      HvacDampr_stReqUdsRcrltnMot: nonqueued-receiver-com-spec{data-element=HvacDampr_stReqUdsRcrltnMot/Val, filter=data-filter-type=ALWAYS, init-value=0}, required-interface=HvacDampr_stReqUdsRcrltnMot
      IoHwAb_HbrModCtrl: client-com-spec=Hbr_SetMod, required-interface=IoHwAb_HbrModCtrl
      IoHwAb_IoDiagHbr: client-com-spec=Hbr_Get, required-interface=IoHwAb_IoDiagHbr
      IoHwAb_IoSigAdc: required-com-specs=[Adc_Get, AdcFac_Get, AdcVRMBatt_Get], required-interface=IoHwAb_IoSigAdc
    behavior HvacDampr_Ctrl_InternalBehavior: data-type-mapping=DTMS_HvacDampr_Ctrl
      timing event TMT_HvacDampr_Ctrl_Runnable_10ms: start-on-event=HvacDampr_Ctrl_Runnable_10ms, period=0.01
      init event HvacDampr_Ctrl_Runnable_InitEvent: start-on-event=HvacDampr_Ctrl_Runnable_Init
      runnable HvacDampr_Ctrl_Runnable_10ms
        data-receive-point-by-arguments:
          33 x access:
            REC_gCFG_u8ReHVACBoxTyp_Val: accessed-variable=gCFG_u8ReHVACBoxTyp.Val
            REC_gPRM_bHotpumpCfg_Val: accessed-variable=gPRM_bHotpumpCfg.Val
            REC_gPRM_u8AirConditionBoxSpecCfg_Val: accessed-variable=gPRM_u8AirConditionBoxSpecCfg.Val
            REC_gPRM_u8ReAirConditionBoxSpecCfg_Val: accessed-variable=gPRM_u8ReAirConditionBoxSpecCfg.Val
            REC_gPRM_u8VehicleTypeCfg_Val: accessed-variable=gPRM_u8VehicleTypeCfg.Val
            REC_HvacDampr_bReqVldDrvrMixMot_Val: accessed-variable=HvacDampr_bReqVldDrvrMixMot.Val
            REC_HvacDampr_bReqVldDrvrRcrltnMot_Val: accessed-variable=HvacDampr_bReqVldDrvrRcrltnMot.Val
            REC_HvacDampr_bReqVldMotMot_Val: accessed-variable=HvacDampr_bReqVldMotMot.Val
            REC_HvacDampr_bReqVldPassMixMot_Val: accessed-variable=HvacDampr_bReqVldPassMixMot.Val
            REC_HvacDampr_bReqVldPassRcrltnMot_Val: accessed-variable=HvacDampr_bReqVldPassRcrltnMot.Val
            REC_HvacDampr_bReqVldRcrltnMot_Val: accessed-variable=HvacDampr_bReqVldRcrltnMot.Val
            REC_HvacDampr_bReqVldReMixMot_Val: accessed-variable=HvacDampr_bReqVldReMixMot.Val
            REC_HvacDampr_bReqVldReMotMot_Val: accessed-variable=HvacDampr_bReqVldReMotMot.Val
            REC_HvacDampr_bUdsTrigDrvrRcrltnMot_Val: accessed-variable=HvacDampr_bUdsTrigDrvrRcrltnMot.Val
            REC_HvacDampr_bUdsTrigModMot_Val: accessed-variable=HvacDampr_bUdsTrigModMot.Val
            REC_HvacDampr_bUdsTrigPassMixMot_Val: accessed-variable=HvacDampr_bUdsTrigPassMixMot.Val
            REC_HvacDampr_bUdsTrigPassRcrltnMot_Val: accessed-variable=HvacDampr_bUdsTrigPassRcrltnMot.Val
            REC_HvacDampr_bUdsTrigPsgrMixMot_Val: accessed-variable=HvacDampr_bUdsTrigPsgrMixMot.Val
            REC_HvacDampr_bUdsTrigRcrltnMot_Val: accessed-variable=HvacDampr_bUdsTrigRcrltnMot.Val
            REC_HvacDampr_stReqDrvrMixMot_Val: accessed-variable=HvacDampr_stReqDrvrMixMot.Val
            REC_HvacDampr_stReqDrvrRcrltnMot_Val: accessed-variable=HvacDampr_stReqDrvrRcrltnMot.Val
            REC_HvacDampr_stReqMotMot_Val: accessed-variable=HvacDampr_stReqMotMot.Val
            REC_HvacDampr_stReqPassMixMot_Val: accessed-variable=HvacDampr_stReqPassMixMot.Val
            REC_HvacDampr_stReqPassRcrltnMot_Val: accessed-variable=HvacDampr_stReqPassRcrltnMot.Val
            REC_HvacDampr_stReqRcrltnMot_Val: accessed-variable=HvacDampr_stReqRcrltnMot.Val
            REC_HvacDampr_stReqReMixMot_Val: accessed-variable=HvacDampr_stReqReMixMot.Val
            REC_HvacDampr_stReqReMotMot_Val: accessed-variable=HvacDampr_stReqReMotMot.Val
            REC_HvacDampr_stReqUdsDrvrRcrltnMot_Val: accessed-variable=HvacDampr_stReqUdsDrvrRcrltnMot.Val
            REC_HvacDampr_stReqUdsModMot_Val: accessed-variable=HvacDampr_stReqUdsModMot.Val
            REC_HvacDampr_stReqUdsPassMixMot_Val: accessed-variable=HvacDampr_stReqUdsPassMixMot.Val
            REC_HvacDampr_stReqUdsPassRcrltnMot_Val: accessed-variable=HvacDampr_stReqUdsPassRcrltnMot.Val
            REC_HvacDampr_stReqUdsPsgrMixMot_Val: accessed-variable=HvacDampr_stReqUdsPsgrMixMot.Val
            REC_HvacDampr_stReqUdsRcrltnMot_Val: accessed-variable=HvacDampr_stReqUdsRcrltnMot.Val
        data-send-points:
          40 x access:
            SEND_HvacDampr_stDrvrMixMotAct_Val: accessed-variable=HvacDampr_stDrvrMixMotAct.Val
            SEND_HvacDampr_stDrvrMixMotDir_Val: accessed-variable=HvacDampr_stDrvrMixMotDir.Val
            SEND_HvacDampr_stDrvrMixMotFlt_Val: accessed-variable=HvacDampr_stDrvrMixMotFlt.Val
            SEND_HvacDampr_stDrvrMixMotRunng_Val: accessed-variable=HvacDampr_stDrvrMixMotRunng.Val
            SEND_HvacDampr_stDrvrRcrltnMotAct_Val: accessed-variable=HvacDampr_stDrvrRcrltnMotAct.Val
            SEND_HvacDampr_stDrvrRcrltnMotDir_Val: accessed-variable=HvacDampr_stDrvrRcrltnMotDir.Val
            SEND_HvacDampr_stDrvrRcrltnMotFlt_Val: accessed-variable=HvacDampr_stDrvrRcrltnMotFlt.Val
            SEND_HvacDampr_stDrvrRcrltnMotRunng_Val: accessed-variable=HvacDampr_stDrvrRcrltnMotRunng.Val
            SEND_HvacDampr_stModMotAct_Val: accessed-variable=HvacDampr_stModMotAct.Val
            SEND_HvacDampr_stModMotDir_Val: accessed-variable=HvacDampr_stModMotDir.Val
            SEND_HvacDampr_stModMotFlt_Val: accessed-variable=HvacDampr_stModMotFlt.Val
            SEND_HvacDampr_stModMotRunng_Val: accessed-variable=HvacDampr_stModMotRunng.Val
            SEND_HvacDampr_stPassMixMotAct_Val: accessed-variable=HvacDampr_stPassMixMotAct.Val
            SEND_HvacDampr_stPassMixMotDir_Val: accessed-variable=HvacDampr_stPassMixMotDir.Val
            SEND_HvacDampr_stPassMixMotFlt_Val: accessed-variable=HvacDampr_stPassMixMotFlt.Val
            SEND_HvacDampr_stPassMixMotRunng_Val: accessed-variable=HvacDampr_stPassMixMotRunng.Val
            SEND_HvacDampr_stPassRcrltnMotAct_Val: accessed-variable=HvacDampr_stPassRcrltnMotAct.Val
            SEND_HvacDampr_stPassRcrltnMotDir_Val: accessed-variable=HvacDampr_stPassRcrltnMotDir.Val
            SEND_HvacDampr_stPassRcrltnMotFlt_Val: accessed-variable=HvacDampr_stPassRcrltnMotFlt.Val
            SEND_HvacDampr_stPassRcrltnMotRunng_Val: accessed-variable=HvacDampr_stPassRcrltnMotRunng.Val
            SEND_HvacDampr_stRcrltnMotAct_Val: accessed-variable=HvacDampr_stRcrltnMotAct.Val
            SEND_HvacDampr_stRcrltnMotDir_Val: accessed-variable=HvacDampr_stRcrltnMotDir.Val
            SEND_HvacDampr_stRcrltnMotFlt_Val: accessed-variable=HvacDampr_stRcrltnMotFlt.Val
            SEND_HvacDampr_stRcrltnMotRunng_Val: accessed-variable=HvacDampr_stRcrltnMotRunng.Val
            SEND_HvacDampr_stReMixMotAct_Val: accessed-variable=HvacDampr_stReMixMotAct.Val
            SEND_HvacDampr_stReMixMotDir_Val: accessed-variable=HvacDampr_stReMixMotDir.Val
            SEND_HvacDampr_stReMixMotFlt_Val: accessed-variable=HvacDampr_stReMixMotFlt.Val
            SEND_HvacDampr_stReMixMotRunng_Val: accessed-variable=HvacDampr_stReMixMotRunng.Val
            SEND_HvacDampr_stReModMotAct_Val: accessed-variable=HvacDampr_stReModMotAct.Val
            SEND_HvacDampr_stReModMotDir_Val: accessed-variable=HvacDampr_stReModMotDir.Val
            SEND_HvacDampr_stReModMotFlt_Val: accessed-variable=HvacDampr_stReModMotFlt.Val
            SEND_HvacDampr_stReModMotRunng_Val: accessed-variable=HvacDampr_stReModMotRunng.Val
            SEND_HvacDampr_uDrvrMixMotFb_Val: accessed-variable=HvacDampr_uDrvrMixMotFb.Val
            SEND_HvacDampr_uDrvrRcrltnMotFb_Val: accessed-variable=HvacDampr_uDrvrRcrltnMotFb.Val
            SEND_HvacDampr_uModMotFb_Val: accessed-variable=HvacDampr_uModMotFb.Val
            SEND_HvacDampr_uPassMixMotFb_Val: accessed-variable=HvacDampr_uPassMixMotFb.Val
            SEND_HvacDampr_uPassRcrltnMotFb_Val: accessed-variable=HvacDampr_uPassRcrltnMotFb.Val
            SEND_HvacDampr_uRcrltnMotFb_Val: accessed-variable=HvacDampr_uRcrltnMotFb.Val
            SEND_HvacDampr_uReMixMotFb_Val: accessed-variable=HvacDampr_uReMixMotFb.Val
            SEND_HvacDampr_uReModMotFb_Val: accessed-variable=HvacDampr_uReModMotFb.Val
        140 x parameter access:
          PA_CAN_CRC_2LAYER_FLOW_VAL: accessed-parameter=CAN_CRC_2LAYER_FLOW_VAL
          PA_CIRCUIT_FAULT_JUDEG_TIME: accessed-parameter=CIRCUIT_FAULT_JUDEG_TIME
          PA_CIRCUIT_NORMAL: accessed-parameter=CIRCUIT_NORMAL
          PA_CIRCUIT_SHORT_GND: accessed-parameter=CIRCUIT_SHORT_GND
          PA_CIRCUIT_SHORT_GND_VAL: accessed-parameter=CIRCUIT_SHORT_GND_VAL
          PA_CIRCUIT_SHORT_POWER: accessed-parameter=CIRCUIT_SHORT_POWER
          PA_CIRCUIT_SHORT_POWER_VAL: accessed-parameter=CIRCUIT_SHORT_POWER_VAL
          PA_DCMOTOR_JAM: accessed-parameter=DCMOTOR_JAM
          PA_DCMOTOR_MODE_BACK_TICKS: accessed-parameter=DCMOTOR_MODE_BACK_TICKS
          PA_DCMOTOR_MODE_DEFMAX_POS: accessed-parameter=DCMOTOR_MODE_DEFMAX_POS
          PA_DCMOTOR_MODE_FACEMIX_POS: accessed-parameter=DCMOTOR_MODE_FACEMIX_POS
          PA_DCMOTOR_MODE_POS_DIFF: accessed-parameter=DCMOTOR_MODE_POS_DIFF
          PA_DCMOTOR_MODE_POS_LIMIT: accessed-parameter=DCMOTOR_MODE_POS_LIMIT
          PA_DCMOTOR_MODE_STALL_TICKS: accessed-parameter=DCMOTOR_MODE_STALL_TICKS
          PA_DCMOTOR_MODE_STOP_TICKS: accessed-parameter=DCMOTOR_MODE_STOP_TICKS
          PA_DCMOTOR_NORMAL: accessed-parameter=DCMOTOR_NORMAL
          PA_DCMOTOR_POS_UNREACHED: accessed-parameter=DCMOTOR_POS_UNREACHED
          PA_HVAC_CRCHmixToPosCnv_CUR: accessed-parameter=HVAC_CRCHmixToPosCnv_CUR
          PA_HVAC_CRCHmixToPosCnv_CUR2: accessed-parameter=HVAC_CRCHmixToPosCnv_CUR2
          PA_HVAC_CRCHmixToPosCnv_CUR3: accessed-parameter=HVAC_CRCHmixToPosCnv_CUR3
          PA_HVAC_CRCPosToHmixCnv_CUR: accessed-parameter=HVAC_CRCPosToHmixCnv_CUR
          PA_HVAC_CRCPosToHmixCnv_CUR2: accessed-parameter=HVAC_CRCPosToHmixCnv_CUR2
          PA_HVAC_CRCPosToHmixCnv_CUR3: accessed-parameter=HVAC_CRCPosToHmixCnv_CUR3
          PA_HVAC_DrTempHmixToPosCnv_CUR: accessed-parameter=HVAC_DrTempHmixToPosCnv_CUR
          PA_HVAC_DrTempHmixToPosCnv_CUR2: accessed-parameter=HVAC_DrTempHmixToPosCnv_CUR2
          PA_HVAC_DrTempHmixToPosCnv_CUR3: accessed-parameter=HVAC_DrTempHmixToPosCnv_CUR3
          PA_HVAC_DrTempPosToHmixCnv_CUR: accessed-parameter=HVAC_DrTempPosToHmixCnv_CUR
          PA_HVAC_DrTempPosToHmixCnv_CUR2: accessed-parameter=HVAC_DrTempPosToHmixCnv_CUR2
          PA_HVAC_DrTempPosToHmixCnv_CUR3: accessed-parameter=HVAC_DrTempPosToHmixCnv_CUR3
          PA_HVAC_PaTempHmixToPosCnv_CUR: accessed-parameter=HVAC_PaTempHmixToPosCnv_CUR
          PA_HVAC_PaTempHmixToPosCnv_CUR2: accessed-parameter=HVAC_PaTempHmixToPosCnv_CUR2
          PA_HVAC_PaTempHmixToPosCnv_CUR3: accessed-parameter=HVAC_PaTempHmixToPosCnv_CUR3
          PA_HVAC_PaTempPosToHmixCnv_CUR: accessed-parameter=HVAC_PaTempPosToHmixCnv_CUR
          PA_HVAC_PaTempPosToHmixCnv_CUR2: accessed-parameter=HVAC_PaTempPosToHmixCnv_CUR2
          PA_HVAC_PaTempPosToHmixCnv_CUR3: accessed-parameter=HVAC_PaTempPosToHmixCnv_CUR3
          PA_HvacDampr_ReTempHmixToPosCnv_CUR: accessed-parameter=HvacDampr_ReTempHmixToPosCnv_CUR
          PA_HvacDampr_ReTempHmixToPosCnv2_CUR: accessed-parameter=HvacDampr_ReTempHmixToPosCnv2_CUR
          PA_HvacDampr_ReTempHmixToPosCnv3_CUR: accessed-parameter=HvacDampr_ReTempHmixToPosCnv3_CUR
          PA_HvacDampr_ReTempPosToHmixCnv_CUR: accessed-parameter=HvacDampr_ReTempPosToHmixCnv_CUR
          PA_HvacDampr_ReTempPosToHmixCnv2_CUR: accessed-parameter=HvacDampr_ReTempPosToHmixCnv2_CUR
          PA_HvacDampr_ReTempPosToHmixCnv3_CUR: accessed-parameter=HvacDampr_ReTempPosToHmixCnv3_CUR
          PA_MDD_CRC_2LAYER_FLOW_SPEC_1: accessed-parameter=MDD_CRC_2LAYER_FLOW_SPEC_1
          PA_MDD_CRC_2LAYER_FLOW_SPEC_2: accessed-parameter=MDD_CRC_2LAYER_FLOW_SPEC_2
          PA_MDD_DEF_POSITION_SPEC_{1..3}: accessed-parameter=MDD_DEF_POSITION_SPEC_{1..3}
          PA_MDD_FLR_POSITION_SPEC_{1..3}: accessed-parameter=MDD_FLR_POSITION_SPEC_{1..3}
          PA_MDD_FLRDEF_POSITION_SPEC_{1..3}: accessed-parameter=MDD_FLRDEF_POSITION_SPEC_{1..3}
          PA_MDD_PNL_POSITION_SPEC_{1..3}: accessed-parameter=MDD_PNL_POSITION_SPEC_{1..3}
          PA_MDD_PNL_VAL: accessed-parameter=MDD_PNL_VAL
          PA_MDD_PNLFLR_POSITION_SPEC_{1..4}: accessed-parameter=MDD_PNLFLR_POSITION_SPEC_{1..4}
          PA_MDD_RE_FLR_POSITION_SPEC_1: accessed-parameter=MDD_RE_FLR_POSITION_SPEC_1
          PA_MDD_RE_PNL_POSITION_SPEC_1: accessed-parameter=MDD_RE_PNL_POSITION_SPEC_1
          PA_MDD_RE_PNLFLR_POSITION_SPEC_1: accessed-parameter=MDD_RE_PNLFLR_POSITION_SPEC_1
          PA_MDD_RE_ST1_POSITION_SPEC_1: accessed-parameter=MDD_RE_ST1_POSITION_SPEC_1
          PA_MDD_RE_ST1_VAL_SPEC1: accessed-parameter=MDD_RE_ST1_VAL_SPEC1
          PA_MDD_RE_ST2_POSITION_SPEC_1: accessed-parameter=MDD_RE_ST2_POSITION_SPEC_1
          PA_MDD_RE_ST2_VAL_SPEC1: accessed-parameter=MDD_RE_ST2_VAL_SPEC1
          PA_MDD_RE_ST3_POSITION_SPEC_1: accessed-parameter=MDD_RE_ST3_POSITION_SPEC_1
          PA_MDD_RE_ST3_VAL_SPEC1: accessed-parameter=MDD_RE_ST3_VAL_SPEC1
          PA_MDD_ST_RE_DIFF_POSITION: accessed-parameter=MDD_ST_RE_DIFF_POSITION
          PA_MDD_ST1_POSITION_SPEC_{1..3}: accessed-parameter=MDD_ST1_POSITION_SPEC_{1..3}
          PA_MDD_ST1_VAL_SPEC{1..3}: accessed-parameter=MDD_ST1_VAL_SPEC{1..3}
          PA_MDD_ST2_POSITION_SPEC_{1..3}: accessed-parameter=MDD_ST2_POSITION_SPEC_{1..3}
          PA_MDD_ST2_VAL_SPEC{1..3}: accessed-parameter=MDD_ST2_VAL_SPEC{1..3}
          PA_MDD_ST3_POSITION_SPEC_{1..3}: accessed-parameter=MDD_ST3_POSITION_SPEC_{1..3}
          PA_MDD_ST3_VAL_SPEC{1..3}: accessed-parameter=MDD_ST3_VAL_SPEC{1..3}
          PA_MDD_ST4_POSITION_SPEC_{1..3}: accessed-parameter=MDD_ST4_POSITION_SPEC_{1..3}
          PA_MDD_ST4_VAL_SPEC{1..3}: accessed-parameter=MDD_ST4_VAL_SPEC{1..3}
          PA_MDD_ST5_POSITION_SPEC_{1..3}: accessed-parameter=MDD_ST5_POSITION_SPEC_{1..3}
          PA_MDD_ST5_VAL_SPEC{1..3}: accessed-parameter=MDD_ST5_VAL_SPEC{1..3}
          PA_MOTO_CRC_SPECT1_P_TURN: accessed-parameter=MOTO_CRC_SPECT1_P_TURN
          PA_MOTO_CRC_SPECT1_R_TURN: accessed-parameter=MOTO_CRC_SPECT1_R_TURN
          PA_MOTO_CRC_SPECT2_P_TURN: accessed-parameter=MOTO_CRC_SPECT2_P_TURN
          PA_MOTO_CRC_SPECT2_R_TURN: accessed-parameter=MOTO_CRC_SPECT2_R_TURN
          PA_MOTO_CRC_SPECT3_P_TURN: accessed-parameter=MOTO_CRC_SPECT3_P_TURN
          PA_MOTO_CRC_SPECT3_R_TURN: accessed-parameter=MOTO_CRC_SPECT3_R_TURN
          PA_MOTO_DR_TEMP_SPECT1_P_TURN: accessed-parameter=MOTO_DR_TEMP_SPECT1_P_TURN
          PA_MOTO_DR_TEMP_SPECT1_R_TURN: accessed-parameter=MOTO_DR_TEMP_SPECT1_R_TURN
          PA_MOTO_DR_TEMP_SPECT2_P_TURN: accessed-parameter=MOTO_DR_TEMP_SPECT2_P_TURN
          PA_MOTO_DR_TEMP_SPECT2_R_TURN: accessed-parameter=MOTO_DR_TEMP_SPECT2_R_TURN
          PA_MOTO_DR_TEMP_SPECT3_P_TURN: accessed-parameter=MOTO_DR_TEMP_SPECT3_P_TURN
          PA_MOTO_DR_TEMP_SPECT3_R_TURN: accessed-parameter=MOTO_DR_TEMP_SPECT3_R_TURN
          PA_MOTO_FALSE_JUDGE_VAL: accessed-parameter=MOTO_FALSE_JUDGE_VAL
          PA_MOTO_INIT_DEAL_TIME: accessed-parameter=MOTO_INIT_DEAL_TIME
          PA_MOTO_MODE_SPECT1_P_TURN: accessed-parameter=MOTO_MODE_SPECT1_P_TURN
          PA_MOTO_MODE_SPECT1_R_TURN: accessed-parameter=MOTO_MODE_SPECT1_R_TURN
          PA_MOTO_MODE_SPECT2_P_TURN: accessed-parameter=MOTO_MODE_SPECT2_P_TURN
          PA_MOTO_MODE_SPECT2_R_TURN: accessed-parameter=MOTO_MODE_SPECT2_R_TURN
          PA_MOTO_MODE_SPECT3_P_TURN: accessed-parameter=MOTO_MODE_SPECT3_P_TURN
          PA_MOTO_MODE_SPECT3_R_TURN: accessed-parameter=MOTO_MODE_SPECT3_R_TURN
          PA_MOTO_PA_TEMP_SPECT1_P_TURN: accessed-parameter=MOTO_PA_TEMP_SPECT1_P_TURN
          PA_MOTO_PA_TEMP_SPECT1_R_TURN: accessed-parameter=MOTO_PA_TEMP_SPECT1_R_TURN
          PA_MOTO_PA_TEMP_SPECT2_P_TURN: accessed-parameter=MOTO_PA_TEMP_SPECT2_P_TURN
          PA_MOTO_PA_TEMP_SPECT2_R_TURN: accessed-parameter=MOTO_PA_TEMP_SPECT2_R_TURN
          PA_MOTO_PA_TEMP_SPECT3_P_TURN: accessed-parameter=MOTO_PA_TEMP_SPECT3_P_TURN
          PA_MOTO_PA_TEMP_SPECT3_R_TURN: accessed-parameter=MOTO_PA_TEMP_SPECT3_R_TURN
          PA_MOTO_RE_TEMP_SPECT1_P_TURN: accessed-parameter=MOTO_RE_TEMP_SPECT1_P_TURN
          PA_MOTO_RE_TEMP_SPECT1_R_TURN: accessed-parameter=MOTO_RE_TEMP_SPECT1_R_TURN
          PA_MOTO_RE_TEMP_SPECT2_P_TURN: accessed-parameter=MOTO_RE_TEMP_SPECT2_P_TURN
          PA_MOTO_RE_TEMP_SPECT2_R_TURN: accessed-parameter=MOTO_RE_TEMP_SPECT2_R_TURN
          PA_MOTO_RE_TEMP_SPECT3_P_TURN: accessed-parameter=MOTO_RE_TEMP_SPECT3_P_TURN
          PA_MOTO_RE_TEMP_SPECT3_R_TURN: accessed-parameter=MOTO_RE_TEMP_SPECT3_R_TURN
          PA_MOTO_REMODE_SPECT1_P_TURN: accessed-parameter=MOTO_REMODE_SPECT1_P_TURN
          PA_MOTO_REMODE_SPECT1_R_TURN: accessed-parameter=MOTO_REMODE_SPECT1_R_TURN
          PA_MOTO_RUNNING: accessed-parameter=MOTO_RUNNING
          PA_MOTO_STOP: accessed-parameter=MOTO_STOP
          PA_MOTO_STOP_RUNNING: accessed-parameter=MOTO_STOP_RUNNING
          PA_PRM_A02_CFG_SPEC_VAL: accessed-parameter=PRM_A02_CFG_SPEC_VAL
          PA_PRM_A08_CFG_SPEC_VAL: accessed-parameter=PRM_A08_CFG_SPEC_VAL
          PA_PRM_A29_CFG_SPEC_VAL: accessed-parameter=PRM_A29_CFG_SPEC_VAL
        53 x sync call:
          SC_DTC_DrvrMixDamprMotMaxErr_GetEventFailed: operation=DTC_DrvrMixDamprMotMaxErr.GetEventFailed, timeout=1E-06
          SC_DTC_DrvrMixDamprMotMaxErr_GetEventTested: operation=DTC_DrvrMixDamprMotMaxErr.GetEventTested, timeout=1E-06
          SC_DTC_DrvrMixDamprMotMaxErr_ResetEventDebounceStatus: operation=DTC_DrvrMixDamprMotMaxErr.ResetEventDebounceStatus, timeout=1E-06
          SC_DTC_DrvrMixDamprMotMaxErr_SetEventStatus: operation=DTC_DrvrMixDamprMotMaxErr.SetEventStatus, timeout=1E-06
          SC_DTC_DrvrMixDamprMotMinErr_GetEventFailed: operation=DTC_DrvrMixDamprMotMinErr.GetEventFailed, timeout=1E-06
          SC_DTC_DrvrMixDamprMotMinErr_GetEventTested: operation=DTC_DrvrMixDamprMotMinErr.GetEventTested, timeout=1E-06
          SC_DTC_DrvrMixDamprMotMinErr_ResetEventDebounceStatus: operation=DTC_DrvrMixDamprMotMinErr.ResetEventDebounceStatus, timeout=1E-06
          SC_DTC_DrvrMixDamprMotMinErr_SetEventStatus: operation=DTC_DrvrMixDamprMotMinErr.SetEventStatus, timeout=1E-06
          SC_DTC_DrvrMixDamprMotStuck_GetEventFailed: operation=DTC_DrvrMixDamprMotStuck.GetEventFailed, timeout=1E-06
          SC_DTC_DrvrMixDamprMotStuck_GetEventTested: operation=DTC_DrvrMixDamprMotStuck.GetEventTested, timeout=1E-06
          SC_DTC_DrvrMixDamprMotStuck_ResetEventDebounceStatus: operation=DTC_DrvrMixDamprMotStuck.ResetEventDebounceStatus, timeout=1E-06
          SC_DTC_DrvrMixDamprMotStuck_SetEventStatus: operation=DTC_DrvrMixDamprMotStuck.SetEventStatus, timeout=1E-06
          SC_DTC_ModDamprMotMaxErr_GetEventFailed: operation=DTC_ModDamprMotMaxErr.GetEventFailed, timeout=1E-06
          SC_DTC_ModDamprMotMaxErr_GetEventTested: operation=DTC_ModDamprMotMaxErr.GetEventTested, timeout=1E-06
          SC_DTC_ModDamprMotMaxErr_ResetEventDebounceStatus: operation=DTC_ModDamprMotMaxErr.ResetEventDebounceStatus, timeout=1E-06
          SC_DTC_ModDamprMotMaxErr_SetEventStatus: operation=DTC_ModDamprMotMaxErr.SetEventStatus, timeout=1E-06
          SC_DTC_ModDamprMotMinErr_GetEventFailed: operation=DTC_ModDamprMotMinErr.GetEventFailed, timeout=1E-06
          SC_DTC_ModDamprMotMinErr_GetEventTested: operation=DTC_ModDamprMotMinErr.GetEventTested, timeout=1E-06
          SC_DTC_ModDamprMotMinErr_ResetEventDebounceStatus: operation=DTC_ModDamprMotMinErr.ResetEventDebounceStatus, timeout=1E-06
          SC_DTC_ModDamprMotMinErr_SetEventStatus: operation=DTC_ModDamprMotMinErr.SetEventStatus, timeout=1E-06
          SC_DTC_ModDamprMotStuck_GetEventFailed: operation=DTC_ModDamprMotStuck.GetEventFailed, timeout=1E-06
          SC_DTC_ModDamprMotStuck_GetEventTested: operation=DTC_ModDamprMotStuck.GetEventTested, timeout=1E-06
          SC_DTC_ModDamprMotStuck_ResetEventDebounceStatus: operation=DTC_ModDamprMotStuck.ResetEventDebounceStatus, timeout=1E-06
          SC_DTC_ModDamprMotStuck_SetEventStatus: operation=DTC_ModDamprMotStuck.SetEventStatus, timeout=1E-06
          SC_DTC_PassMixDamprMotMaxErr_GetEventFailed: operation=DTC_PassMixDamprMotMaxErr.GetEventFailed, timeout=1E-06
          SC_DTC_PassMixDamprMotMaxErr_GetEventTested: operation=DTC_PassMixDamprMotMaxErr.GetEventTested, timeout=1E-06
          SC_DTC_PassMixDamprMotMaxErr_ResetEventDebounceStatus: operation=DTC_PassMixDamprMotMaxErr.ResetEventDebounceStatus, timeout=1E-06
          SC_DTC_PassMixDamprMotMaxErr_SetEventStatus: operation=DTC_PassMixDamprMotMaxErr.SetEventStatus, timeout=1E-06
          SC_DTC_PassMixDamprMotMinErr_GetEventFailed: operation=DTC_PassMixDamprMotMinErr.GetEventFailed, timeout=1E-06
          SC_DTC_PassMixDamprMotMinErr_GetEventTested: operation=DTC_PassMixDamprMotMinErr.GetEventTested, timeout=1E-06
          SC_DTC_PassMixDamprMotMinErr_ResetEventDebounceStatus: operation=DTC_PassMixDamprMotMinErr.ResetEventDebounceStatus, timeout=1E-06
          SC_DTC_PassMixDamprMotMinErr_SetEventStatus: operation=DTC_PassMixDamprMotMinErr.SetEventStatus, timeout=1E-06
          SC_DTC_PassMixDamprMotStuck_GetEventFailed: operation=DTC_PassMixDamprMotStuck.GetEventFailed, timeout=1E-06
          SC_DTC_PassMixDamprMotStuck_GetEventTested: operation=DTC_PassMixDamprMotStuck.GetEventTested, timeout=1E-06
          SC_DTC_PassMixDamprMotStuck_ResetEventDebounceStatus: operation=DTC_PassMixDamprMotStuck.ResetEventDebounceStatus, timeout=1E-06
          SC_DTC_PassMixDamprMotStuck_SetEventStatus: operation=DTC_PassMixDamprMotStuck.SetEventStatus, timeout=1E-06
          SC_DTC_RcrltnDamprMotMaxErr_GetEventFailed: operation=DTC_RcrltnDamprMotMaxErr.GetEventFailed, timeout=1E-06
          SC_DTC_RcrltnDamprMotMaxErr_GetEventTested: operation=DTC_RcrltnDamprMotMaxErr.GetEventTested, timeout=1E-06
          SC_DTC_RcrltnDamprMotMaxErr_ResetEventDebounceStatus: operation=DTC_RcrltnDamprMotMaxErr.ResetEventDebounceStatus, timeout=1E-06
          SC_DTC_RcrltnDamprMotMaxErr_SetEventStatus: operation=DTC_RcrltnDamprMotMaxErr.SetEventStatus, timeout=1E-06
          SC_DTC_RcrltnDamprMotMinErr_GetEventFailed: operation=DTC_RcrltnDamprMotMinErr.GetEventFailed, timeout=1E-06
          SC_DTC_RcrltnDamprMotMinErr_GetEventTested: operation=DTC_RcrltnDamprMotMinErr.GetEventTested, timeout=1E-06
          SC_DTC_RcrltnDamprMotMinErr_ResetEventDebounceStatus: operation=DTC_RcrltnDamprMotMinErr.ResetEventDebounceStatus, timeout=1E-06
          SC_DTC_RcrltnDamprMotMinErr_SetEventStatus: operation=DTC_RcrltnDamprMotMinErr.SetEventStatus, timeout=1E-06
          SC_DTC_RcrltnDamprMotStuck_GetEventFailed: operation=DTC_RcrltnDamprMotStuck.GetEventFailed, timeout=1E-06
          SC_DTC_RcrltnDamprMotStuck_GetEventTested: operation=DTC_RcrltnDamprMotStuck.GetEventTested, timeout=1E-06
          SC_DTC_RcrltnDamprMotStuck_ResetEventDebounceStatus: operation=DTC_RcrltnDamprMotStuck.ResetEventDebounceStatus, timeout=1E-06
          SC_DTC_RcrltnDamprMotStuck_SetEventStatus: operation=DTC_RcrltnDamprMotStuck.SetEventStatus, timeout=1E-06
          SC_IoHwAb_HbrModCtrl_Hbr_SetMod: operation=IoHwAb_HbrModCtrl.Hbr_SetMod, timeout=0
          SC_IoHwAb_IoDiagHbr_Hbr_Get: operation=IoHwAb_IoDiagHbr.Hbr_Get, timeout=0
          SC_IoHwAb_IoSigAdc_Adc_Get: operation=IoHwAb_IoSigAdc.Adc_Get, timeout=0
          SC_IoHwAb_IoSigAdc_AdcFac_Get: operation=IoHwAb_IoSigAdc.AdcFac_Get, timeout=0
          SC_IoHwAb_IoSigAdc_AdcVRMBatt_Get: operation=IoHwAb_IoSigAdc.AdcVRMBatt_Get, timeout=0
      runnable HvacDampr_Ctrl_Runnable_Init
        data-receive-point-by-arguments:
          33 x access:
            REC_gCFG_u8ReHVACBoxTyp_Val: accessed-variable=gCFG_u8ReHVACBoxTyp.Val
            REC_gPRM_bHotpumpCfg_Val: accessed-variable=gPRM_bHotpumpCfg.Val
            REC_gPRM_u8AirConditionBoxSpecCfg_Val: accessed-variable=gPRM_u8AirConditionBoxSpecCfg.Val
            REC_gPRM_u8ReAirConditionBoxSpecCfg_Val: accessed-variable=gPRM_u8ReAirConditionBoxSpecCfg.Val
            REC_gPRM_u8VehicleTypeCfg_Val: accessed-variable=gPRM_u8VehicleTypeCfg.Val
            REC_HvacDampr_bReqVldDrvrMixMot_Val: accessed-variable=HvacDampr_bReqVldDrvrMixMot.Val
            REC_HvacDampr_bReqVldDrvrRcrltnMot_Val: accessed-variable=HvacDampr_bReqVldDrvrRcrltnMot.Val
            REC_HvacDampr_bReqVldMotMot_Val: accessed-variable=HvacDampr_bReqVldMotMot.Val
            REC_HvacDampr_bReqVldPassMixMot_Val: accessed-variable=HvacDampr_bReqVldPassMixMot.Val
            REC_HvacDampr_bReqVldPassRcrltnMot_Val: accessed-variable=HvacDampr_bReqVldPassRcrltnMot.Val
            REC_HvacDampr_bReqVldRcrltnMot_Val: accessed-variable=HvacDampr_bReqVldRcrltnMot.Val
            REC_HvacDampr_bReqVldReMixMot_Val: accessed-variable=HvacDampr_bReqVldReMixMot.Val
            REC_HvacDampr_bReqVldReMotMot_Val: accessed-variable=HvacDampr_bReqVldReMotMot.Val
            REC_HvacDampr_bUdsTrigDrvrRcrltnMot_Val: accessed-variable=HvacDampr_bUdsTrigDrvrRcrltnMot.Val
            REC_HvacDampr_bUdsTrigModMot_Val: accessed-variable=HvacDampr_bUdsTrigModMot.Val
            REC_HvacDampr_bUdsTrigPassMixMot_Val: accessed-variable=HvacDampr_bUdsTrigPassMixMot.Val
            REC_HvacDampr_bUdsTrigPassRcrltnMot_Val: accessed-variable=HvacDampr_bUdsTrigPassRcrltnMot.Val
            REC_HvacDampr_bUdsTrigPsgrMixMot_Val: accessed-variable=HvacDampr_bUdsTrigPsgrMixMot.Val
            REC_HvacDampr_bUdsTrigRcrltnMot_Val: accessed-variable=HvacDampr_bUdsTrigRcrltnMot.Val
            REC_HvacDampr_stReqDrvrMixMot_Val: accessed-variable=HvacDampr_stReqDrvrMixMot.Val
            REC_HvacDampr_stReqDrvrRcrltnMot_Val: accessed-variable=HvacDampr_stReqDrvrRcrltnMot.Val
            REC_HvacDampr_stReqMotMot_Val: accessed-variable=HvacDampr_stReqMotMot.Val
            REC_HvacDampr_stReqPassMixMot_Val: accessed-variable=HvacDampr_stReqPassMixMot.Val
            REC_HvacDampr_stReqPassRcrltnMot_Val: accessed-variable=HvacDampr_stReqPassRcrltnMot.Val
            REC_HvacDampr_stReqRcrltnMot_Val: accessed-variable=HvacDampr_stReqRcrltnMot.Val
            REC_HvacDampr_stReqReMixMot_Val: accessed-variable=HvacDampr_stReqReMixMot.Val
            REC_HvacDampr_stReqReMotMot_Val: accessed-variable=HvacDampr_stReqReMotMot.Val
            REC_HvacDampr_stReqUdsDrvrRcrltnMot_Val: accessed-variable=HvacDampr_stReqUdsDrvrRcrltnMot.Val
            REC_HvacDampr_stReqUdsModMot_Val: accessed-variable=HvacDampr_stReqUdsModMot.Val
            REC_HvacDampr_stReqUdsPassMixMot_Val: accessed-variable=HvacDampr_stReqUdsPassMixMot.Val
            REC_HvacDampr_stReqUdsPassRcrltnMot_Val: accessed-variable=HvacDampr_stReqUdsPassRcrltnMot.Val
            REC_HvacDampr_stReqUdsPsgrMixMot_Val: accessed-variable=HvacDampr_stReqUdsPsgrMixMot.Val
            REC_HvacDampr_stReqUdsRcrltnMot_Val: accessed-variable=HvacDampr_stReqUdsRcrltnMot.Val
        data-send-points:
          40 x access:
            SEND_HvacDampr_stDrvrMixMotAct_Val: accessed-variable=HvacDampr_stDrvrMixMotAct.Val
            SEND_HvacDampr_stDrvrMixMotDir_Val: accessed-variable=HvacDampr_stDrvrMixMotDir.Val
            SEND_HvacDampr_stDrvrMixMotFlt_Val: accessed-variable=HvacDampr_stDrvrMixMotFlt.Val
            SEND_HvacDampr_stDrvrMixMotRunng_Val: accessed-variable=HvacDampr_stDrvrMixMotRunng.Val
            SEND_HvacDampr_stDrvrRcrltnMotAct_Val: accessed-variable=HvacDampr_stDrvrRcrltnMotAct.Val
            SEND_HvacDampr_stDrvrRcrltnMotDir_Val: accessed-variable=HvacDampr_stDrvrRcrltnMotDir.Val
            SEND_HvacDampr_stDrvrRcrltnMotFlt_Val: accessed-variable=HvacDampr_stDrvrRcrltnMotFlt.Val
            SEND_HvacDampr_stDrvrRcrltnMotRunng_Val: accessed-variable=HvacDampr_stDrvrRcrltnMotRunng.Val
            SEND_HvacDampr_stModMotAct_Val: accessed-variable=HvacDampr_stModMotAct.Val
            SEND_HvacDampr_stModMotDir_Val: accessed-variable=HvacDampr_stModMotDir.Val
            SEND_HvacDampr_stModMotFlt_Val: accessed-variable=HvacDampr_stModMotFlt.Val
            SEND_HvacDampr_stModMotRunng_Val: accessed-variable=HvacDampr_stModMotRunng.Val
            SEND_HvacDampr_stPassMixMotAct_Val: accessed-variable=HvacDampr_stPassMixMotAct.Val
            SEND_HvacDampr_stPassMixMotDir_Val: accessed-variable=HvacDampr_stPassMixMotDir.Val
            SEND_HvacDampr_stPassMixMotFlt_Val: accessed-variable=HvacDampr_stPassMixMotFlt.Val
            SEND_HvacDampr_stPassMixMotRunng_Val: accessed-variable=HvacDampr_stPassMixMotRunng.Val
            SEND_HvacDampr_stPassRcrltnMotAct_Val: accessed-variable=HvacDampr_stPassRcrltnMotAct.Val
            SEND_HvacDampr_stPassRcrltnMotDir_Val: accessed-variable=HvacDampr_stPassRcrltnMotDir.Val
            SEND_HvacDampr_stPassRcrltnMotFlt_Val: accessed-variable=HvacDampr_stPassRcrltnMotFlt.Val
            SEND_HvacDampr_stPassRcrltnMotRunng_Val: accessed-variable=HvacDampr_stPassRcrltnMotRunng.Val
            SEND_HvacDampr_stRcrltnMotAct_Val: accessed-variable=HvacDampr_stRcrltnMotAct.Val
            SEND_HvacDampr_stRcrltnMotDir_Val: accessed-variable=HvacDampr_stRcrltnMotDir.Val
            SEND_HvacDampr_stRcrltnMotFlt_Val: accessed-variable=HvacDampr_stRcrltnMotFlt.Val
            SEND_HvacDampr_stRcrltnMotRunng_Val: accessed-variable=HvacDampr_stRcrltnMotRunng.Val
            SEND_HvacDampr_stReMixMotAct_Val: accessed-variable=HvacDampr_stReMixMotAct.Val
            SEND_HvacDampr_stReMixMotDir_Val: accessed-variable=HvacDampr_stReMixMotDir.Val
            SEND_HvacDampr_stReMixMotFlt_Val: accessed-variable=HvacDampr_stReMixMotFlt.Val
            SEND_HvacDampr_stReMixMotRunng_Val: accessed-variable=HvacDampr_stReMixMotRunng.Val
            SEND_HvacDampr_stReModMotAct_Val: accessed-variable=HvacDampr_stReModMotAct.Val
            SEND_HvacDampr_stReModMotDir_Val: accessed-variable=HvacDampr_stReModMotDir.Val
            SEND_HvacDampr_stReModMotFlt_Val: accessed-variable=HvacDampr_stReModMotFlt.Val
            SEND_HvacDampr_stReModMotRunng_Val: accessed-variable=HvacDampr_stReModMotRunng.Val
            SEND_HvacDampr_uDrvrMixMotFb_Val: accessed-variable=HvacDampr_uDrvrMixMotFb.Val
            SEND_HvacDampr_uDrvrRcrltnMotFb_Val: accessed-variable=HvacDampr_uDrvrRcrltnMotFb.Val
            SEND_HvacDampr_uModMotFb_Val: accessed-variable=HvacDampr_uModMotFb.Val
            SEND_HvacDampr_uPassMixMotFb_Val: accessed-variable=HvacDampr_uPassMixMotFb.Val
            SEND_HvacDampr_uPassRcrltnMotFb_Val: accessed-variable=HvacDampr_uPassRcrltnMotFb.Val
            SEND_HvacDampr_uRcrltnMotFb_Val: accessed-variable=HvacDampr_uRcrltnMotFb.Val
            SEND_HvacDampr_uReMixMotFb_Val: accessed-variable=HvacDampr_uReMixMotFb.Val
            SEND_HvacDampr_uReModMotFb_Val: accessed-variable=HvacDampr_uReModMotFb.Val
        140 x parameter access:
          PA_CAN_CRC_2LAYER_FLOW_VAL: accessed-parameter=CAN_CRC_2LAYER_FLOW_VAL
          PA_CIRCUIT_FAULT_JUDEG_TIME: accessed-parameter=CIRCUIT_FAULT_JUDEG_TIME
          PA_CIRCUIT_NORMAL: accessed-parameter=CIRCUIT_NORMAL
          PA_CIRCUIT_SHORT_GND: accessed-parameter=CIRCUIT_SHORT_GND
          PA_CIRCUIT_SHORT_GND_VAL: accessed-parameter=CIRCUIT_SHORT_GND_VAL
          PA_CIRCUIT_SHORT_POWER: accessed-parameter=CIRCUIT_SHORT_POWER
          PA_CIRCUIT_SHORT_POWER_VAL: accessed-parameter=CIRCUIT_SHORT_POWER_VAL
          PA_DCMOTOR_JAM: accessed-parameter=DCMOTOR_JAM
          PA_DCMOTOR_MODE_BACK_TICKS: accessed-parameter=DCMOTOR_MODE_BACK_TICKS
          PA_DCMOTOR_MODE_DEFMAX_POS: accessed-parameter=DCMOTOR_MODE_DEFMAX_POS
          PA_DCMOTOR_MODE_FACEMIX_POS: accessed-parameter=DCMOTOR_MODE_FACEMIX_POS
          PA_DCMOTOR_MODE_POS_DIFF: accessed-parameter=DCMOTOR_MODE_POS_DIFF
          PA_DCMOTOR_MODE_POS_LIMIT: accessed-parameter=DCMOTOR_MODE_POS_LIMIT
          PA_DCMOTOR_MODE_STALL_TICKS: accessed-parameter=DCMOTOR_MODE_STALL_TICKS
          PA_DCMOTOR_MODE_STOP_TICKS: accessed-parameter=DCMOTOR_MODE_STOP_TICKS
          PA_DCMOTOR_NORMAL: accessed-parameter=DCMOTOR_NORMAL
          PA_DCMOTOR_POS_UNREACHED: accessed-parameter=DCMOTOR_POS_UNREACHED
          PA_HVAC_CRCHmixToPosCnv_CUR: accessed-parameter=HVAC_CRCHmixToPosCnv_CUR
          PA_HVAC_CRCHmixToPosCnv_CUR2: accessed-parameter=HVAC_CRCHmixToPosCnv_CUR2
          PA_HVAC_CRCHmixToPosCnv_CUR3: accessed-parameter=HVAC_CRCHmixToPosCnv_CUR3
          PA_HVAC_CRCPosToHmixCnv_CUR: accessed-parameter=HVAC_CRCPosToHmixCnv_CUR
          PA_HVAC_CRCPosToHmixCnv_CUR2: accessed-parameter=HVAC_CRCPosToHmixCnv_CUR2
          PA_HVAC_CRCPosToHmixCnv_CUR3: accessed-parameter=HVAC_CRCPosToHmixCnv_CUR3
          PA_HVAC_DrTempHmixToPosCnv_CUR: accessed-parameter=HVAC_DrTempHmixToPosCnv_CUR
          PA_HVAC_DrTempHmixToPosCnv_CUR2: accessed-parameter=HVAC_DrTempHmixToPosCnv_CUR2
          PA_HVAC_DrTempHmixToPosCnv_CUR3: accessed-parameter=HVAC_DrTempHmixToPosCnv_CUR3
          PA_HVAC_DrTempPosToHmixCnv_CUR: accessed-parameter=HVAC_DrTempPosToHmixCnv_CUR
          PA_HVAC_DrTempPosToHmixCnv_CUR2: accessed-parameter=HVAC_DrTempPosToHmixCnv_CUR2
          PA_HVAC_DrTempPosToHmixCnv_CUR3: accessed-parameter=HVAC_DrTempPosToHmixCnv_CUR3
          PA_HVAC_PaTempHmixToPosCnv_CUR: accessed-parameter=HVAC_PaTempHmixToPosCnv_CUR
          PA_HVAC_PaTempHmixToPosCnv_CUR2: accessed-parameter=HVAC_PaTempHmixToPosCnv_CUR2
          PA_HVAC_PaTempHmixToPosCnv_CUR3: accessed-parameter=HVAC_PaTempHmixToPosCnv_CUR3
          PA_HVAC_PaTempPosToHmixCnv_CUR: accessed-parameter=HVAC_PaTempPosToHmixCnv_CUR
          PA_HVAC_PaTempPosToHmixCnv_CUR2: accessed-parameter=HVAC_PaTempPosToHmixCnv_CUR2
          PA_HVAC_PaTempPosToHmixCnv_CUR3: accessed-parameter=HVAC_PaTempPosToHmixCnv_CUR3
          PA_HvacDampr_ReTempHmixToPosCnv_CUR: accessed-parameter=HvacDampr_ReTempHmixToPosCnv_CUR
          PA_HvacDampr_ReTempHmixToPosCnv2_CUR: accessed-parameter=HvacDampr_ReTempHmixToPosCnv2_CUR
          PA_HvacDampr_ReTempHmixToPosCnv3_CUR: accessed-parameter=HvacDampr_ReTempHmixToPosCnv3_CUR
          PA_HvacDampr_ReTempPosToHmixCnv_CUR: accessed-parameter=HvacDampr_ReTempPosToHmixCnv_CUR
          PA_HvacDampr_ReTempPosToHmixCnv2_CUR: accessed-parameter=HvacDampr_ReTempPosToHmixCnv2_CUR
          PA_HvacDampr_ReTempPosToHmixCnv3_CUR: accessed-parameter=HvacDampr_ReTempPosToHmixCnv3_CUR
          PA_MDD_CRC_2LAYER_FLOW_SPEC_1: accessed-parameter=MDD_CRC_2LAYER_FLOW_SPEC_1
          PA_MDD_CRC_2LAYER_FLOW_SPEC_2: accessed-parameter=MDD_CRC_2LAYER_FLOW_SPEC_2
          PA_MDD_DEF_POSITION_SPEC_{1..3}: accessed-parameter=MDD_DEF_POSITION_SPEC_{1..3}
          PA_MDD_FLR_POSITION_SPEC_{1..3}: accessed-parameter=MDD_FLR_POSITION_SPEC_{1..3}
          PA_MDD_FLRDEF_POSITION_SPEC_{1..3}: accessed-parameter=MDD_FLRDEF_POSITION_SPEC_{1..3}
          PA_MDD_PNL_POSITION_SPEC_{1..3}: accessed-parameter=MDD_PNL_POSITION_SPEC_{1..3}
          PA_MDD_PNL_VAL: accessed-parameter=MDD_PNL_VAL
          PA_MDD_PNLFLR_POSITION_SPEC_{1..4}: accessed-parameter=MDD_PNLFLR_POSITION_SPEC_{1..4}
          PA_MDD_RE_FLR_POSITION_SPEC_1: accessed-parameter=MDD_RE_FLR_POSITION_SPEC_1
          PA_MDD_RE_PNL_POSITION_SPEC_1: accessed-parameter=MDD_RE_PNL_POSITION_SPEC_1
          PA_MDD_RE_PNLFLR_POSITION_SPEC_1: accessed-parameter=MDD_RE_PNLFLR_POSITION_SPEC_1
          PA_MDD_RE_ST1_POSITION_SPEC_1: accessed-parameter=MDD_RE_ST1_POSITION_SPEC_1
          PA_MDD_RE_ST1_VAL_SPEC1: accessed-parameter=MDD_RE_ST1_VAL_SPEC1
          PA_MDD_RE_ST2_POSITION_SPEC_1: accessed-parameter=MDD_RE_ST2_POSITION_SPEC_1
          PA_MDD_RE_ST2_VAL_SPEC1: accessed-parameter=MDD_RE_ST2_VAL_SPEC1
          PA_MDD_RE_ST3_POSITION_SPEC_1: accessed-parameter=MDD_RE_ST3_POSITION_SPEC_1
          PA_MDD_RE_ST3_VAL_SPEC1: accessed-parameter=MDD_RE_ST3_VAL_SPEC1
          PA_MDD_ST_RE_DIFF_POSITION: accessed-parameter=MDD_ST_RE_DIFF_POSITION
          PA_MDD_ST1_POSITION_SPEC_{1..3}: accessed-parameter=MDD_ST1_POSITION_SPEC_{1..3}
          PA_MDD_ST1_VAL_SPEC{1..3}: accessed-parameter=MDD_ST1_VAL_SPEC{1..3}
          PA_MDD_ST2_POSITION_SPEC_{1..3}: accessed-parameter=MDD_ST2_POSITION_SPEC_{1..3}
          PA_MDD_ST2_VAL_SPEC{1..3}: accessed-parameter=MDD_ST2_VAL_SPEC{1..3}
          PA_MDD_ST3_POSITION_SPEC_{1..3}: accessed-parameter=MDD_ST3_POSITION_SPEC_{1..3}
          PA_MDD_ST3_VAL_SPEC{1..3}: accessed-parameter=MDD_ST3_VAL_SPEC{1..3}
          PA_MDD_ST4_POSITION_SPEC_{1..3}: accessed-parameter=MDD_ST4_POSITION_SPEC_{1..3}
          PA_MDD_ST4_VAL_SPEC{1..3}: accessed-parameter=MDD_ST4_VAL_SPEC{1..3}
          PA_MDD_ST5_POSITION_SPEC_{1..3}: accessed-parameter=MDD_ST5_POSITION_SPEC_{1..3}
          PA_MDD_ST5_VAL_SPEC{1..3}: accessed-parameter=MDD_ST5_VAL_SPEC{1..3}
          PA_MOTO_CRC_SPECT1_P_TURN: accessed-parameter=MOTO_CRC_SPECT1_P_TURN
          PA_MOTO_CRC_SPECT1_R_TURN: accessed-parameter=MOTO_CRC_SPECT1_R_TURN
          PA_MOTO_CRC_SPECT2_P_TURN: accessed-parameter=MOTO_CRC_SPECT2_P_TURN
          PA_MOTO_CRC_SPECT2_R_TURN: accessed-parameter=MOTO_CRC_SPECT2_R_TURN
          PA_MOTO_CRC_SPECT3_P_TURN: accessed-parameter=MOTO_CRC_SPECT3_P_TURN
          PA_MOTO_CRC_SPECT3_R_TURN: accessed-parameter=MOTO_CRC_SPECT3_R_TURN
          PA_MOTO_DR_TEMP_SPECT1_P_TURN: accessed-parameter=MOTO_DR_TEMP_SPECT1_P_TURN
          PA_MOTO_DR_TEMP_SPECT1_R_TURN: accessed-parameter=MOTO_DR_TEMP_SPECT1_R_TURN
          PA_MOTO_DR_TEMP_SPECT2_P_TURN: accessed-parameter=MOTO_DR_TEMP_SPECT2_P_TURN
          PA_MOTO_DR_TEMP_SPECT2_R_TURN: accessed-parameter=MOTO_DR_TEMP_SPECT2_R_TURN
          PA_MOTO_DR_TEMP_SPECT3_P_TURN: accessed-parameter=MOTO_DR_TEMP_SPECT3_P_TURN
          PA_MOTO_DR_TEMP_SPECT3_R_TURN: accessed-parameter=MOTO_DR_TEMP_SPECT3_R_TURN
          PA_MOTO_FALSE_JUDGE_VAL: accessed-parameter=MOTO_FALSE_JUDGE_VAL
          PA_MOTO_INIT_DEAL_TIME: accessed-parameter=MOTO_INIT_DEAL_TIME
          PA_MOTO_MODE_SPECT1_P_TURN: accessed-parameter=MOTO_MODE_SPECT1_P_TURN
          PA_MOTO_MODE_SPECT1_R_TURN: accessed-parameter=MOTO_MODE_SPECT1_R_TURN
          PA_MOTO_MODE_SPECT2_P_TURN: accessed-parameter=MOTO_MODE_SPECT2_P_TURN
          PA_MOTO_MODE_SPECT2_R_TURN: accessed-parameter=MOTO_MODE_SPECT2_R_TURN
          PA_MOTO_MODE_SPECT3_P_TURN: accessed-parameter=MOTO_MODE_SPECT3_P_TURN
          PA_MOTO_MODE_SPECT3_R_TURN: accessed-parameter=MOTO_MODE_SPECT3_R_TURN
          PA_MOTO_PA_TEMP_SPECT1_P_TURN: accessed-parameter=MOTO_PA_TEMP_SPECT1_P_TURN
          PA_MOTO_PA_TEMP_SPECT1_R_TURN: accessed-parameter=MOTO_PA_TEMP_SPECT1_R_TURN
          PA_MOTO_PA_TEMP_SPECT2_P_TURN: accessed-parameter=MOTO_PA_TEMP_SPECT2_P_TURN
          PA_MOTO_PA_TEMP_SPECT2_R_TURN: accessed-parameter=MOTO_PA_TEMP_SPECT2_R_TURN
          PA_MOTO_PA_TEMP_SPECT3_P_TURN: accessed-parameter=MOTO_PA_TEMP_SPECT3_P_TURN
          PA_MOTO_PA_TEMP_SPECT3_R_TURN: accessed-parameter=MOTO_PA_TEMP_SPECT3_R_TURN
          PA_MOTO_RE_TEMP_SPECT1_P_TURN: accessed-parameter=MOTO_RE_TEMP_SPECT1_P_TURN
          PA_MOTO_RE_TEMP_SPECT1_R_TURN: accessed-parameter=MOTO_RE_TEMP_SPECT1_R_TURN
          PA_MOTO_RE_TEMP_SPECT2_P_TURN: accessed-parameter=MOTO_RE_TEMP_SPECT2_P_TURN
          PA_MOTO_RE_TEMP_SPECT2_R_TURN: accessed-parameter=MOTO_RE_TEMP_SPECT2_R_TURN
          PA_MOTO_RE_TEMP_SPECT3_P_TURN: accessed-parameter=MOTO_RE_TEMP_SPECT3_P_TURN
          PA_MOTO_RE_TEMP_SPECT3_R_TURN: accessed-parameter=MOTO_RE_TEMP_SPECT3_R_TURN
          PA_MOTO_REMODE_SPECT1_P_TURN: accessed-parameter=MOTO_REMODE_SPECT1_P_TURN
          PA_MOTO_REMODE_SPECT1_R_TURN: accessed-parameter=MOTO_REMODE_SPECT1_R_TURN
          PA_MOTO_RUNNING: accessed-parameter=MOTO_RUNNING
          PA_MOTO_STOP: accessed-parameter=MOTO_STOP
          PA_MOTO_STOP_RUNNING: accessed-parameter=MOTO_STOP_RUNNING
          PA_PRM_A02_CFG_SPEC_VAL: accessed-parameter=PRM_A02_CFG_SPEC_VAL
          PA_PRM_A08_CFG_SPEC_VAL: accessed-parameter=PRM_A08_CFG_SPEC_VAL
          PA_PRM_A29_CFG_SPEC_VAL: accessed-parameter=PRM_A29_CFG_SPEC_VAL
        sync call SC_IoHwAb_HbrModCtrl_Hbr_SetMod: operation=IoHwAb_HbrModCtrl.Hbr_SetMod, timeout=0
        sync call SC_IoHwAb_IoDiagHbr_Hbr_Get: operation=IoHwAb_IoDiagHbr.Hbr_Get, timeout=0
        sync call SC_IoHwAb_IoSigAdc_AdcFac_Get: operation=IoHwAb_IoSigAdc.AdcFac_Get, timeout=0
      shared-parameters:
        140 x parameter data prototype, all with sw-addr-method=CALDATA, sw-calibration-access=READ-WRITE:
          CAN_CRC_2LAYER_FLOW_VAL: type=ImplementationDataTypes/uint8, init-value=constant-reference={short-label=CAN_CRC_2LAYER_FLOW_VAL, constant=CAN_CRC_2LAYER_FLOW_VAL}
          CIRCUIT_FAULT_JUDEG_TIME: type=ImplementationDataTypes/uint16, init-value=constant-reference={short-label=CIRCUIT_FAULT_JUDEG_TIME, constant=CIRCUIT_FAULT_JUDEG_TIME}
          CIRCUIT_NORMAL: type=ImplementationDataTypes/uint8, init-value=constant-reference={short-label=CIRCUIT_NORMAL, constant=CIRCUIT_NORMAL}
          CIRCUIT_SHORT_GND: type=ImplementationDataTypes/uint8, init-value=constant-reference={short-label=CIRCUIT_SHORT_GND, constant=CIRCUIT_SHORT_GND}
          CIRCUIT_SHORT_GND_VAL: type=ImplementationDataTypes/uint16, init-value=constant-reference={short-label=CIRCUIT_SHORT_GND_VAL, constant=CIRCUIT_SHORT_GND_VAL}
          CIRCUIT_SHORT_POWER: type=ImplementationDataTypes/uint8, init-value=constant-reference={short-label=CIRCUIT_SHORT_POWER, constant=CIRCUIT_SHORT_POWER}
          CIRCUIT_SHORT_POWER_VAL: type=ImplementationDataTypes/uint16, init-value=constant-reference={short-label=CIRCUIT_SHORT_POWER_VAL, constant=CIRCUIT_SHORT_POWER_VAL}
          DCMOTOR_JAM: type=ImplementationDataTypes/uint8, init-value=constant-reference={short-label=DCMOTOR_JAM, constant=DCMOTOR_JAM}
          DCMOTOR_MODE_BACK_TICKS: type=ImplementationDataTypes/uint16, init-value=constant-reference={short-label=DCMOTOR_MODE_BACK_TICKS, constant=DCMOTOR_MODE_BACK_TICKS}
          DCMOTOR_MODE_DEFMAX_POS: type=ImplementationDataTypes/uint16, init-value=constant-reference={short-label=DCMOTOR_MODE_DEFMAX_POS, constant=DCMOTOR_MODE_DEFMAX_POS}
          DCMOTOR_MODE_FACEMIX_POS: type=ImplementationDataTypes/uint16, init-value=constant-reference={short-label=DCMOTOR_MODE_FACEMIX_POS, constant=DCMOTOR_MODE_FACEMIX_POS}
          DCMOTOR_MODE_POS_DIFF: type=ImplementationDataTypes/uint16, init-value=constant-reference={short-label=DCMOTOR_MODE_POS_DIFF, constant=DCMOTOR_MODE_POS_DIFF}
          DCMOTOR_MODE_POS_LIMIT: type=ImplementationDataTypes/uint16, init-value=constant-reference={short-label=DCMOTOR_MODE_POS_LIMIT, constant=DCMOTOR_MODE_POS_LIMIT}
          DCMOTOR_MODE_STALL_TICKS: type=ImplementationDataTypes/uint16, init-value=constant-reference={short-label=DCMOTOR_MODE_STALL_TICKS, constant=DCMOTOR_MODE_STALL_TICKS}
          DCMOTOR_MODE_STOP_TICKS: type=ImplementationDataTypes/uint16, init-value=constant-reference={short-label=DCMOTOR_MODE_STOP_TICKS, constant=DCMOTOR_MODE_STOP_TICKS}
          DCMOTOR_NORMAL: type=ImplementationDataTypes/uint8, init-value=constant-reference={short-label=DCMOTOR_NORMAL, constant=DCMOTOR_NORMAL}
          DCMOTOR_POS_UNREACHED: type=ImplementationDataTypes/uint8, init-value=constant-reference={short-label=DCMOTOR_POS_UNREACHED, constant=DCMOTOR_POS_UNREACHED}
          HVAC_CRCHmixToPosCnv_CUR: type=Appl_HVAC_CRCHmixToPosCnv_CUR, init-value=constant-reference={short-label=HVAC_CRCHmixToPosCnv_CUR, constant=HVAC_CRCHmixToPosCnv_CUR}
          HVAC_CRCHmixToPosCnv_CUR2: type=Appl_HVAC_CRCHmixToPosCnv_CUR2, init-value=constant-reference={short-label=HVAC_CRCHmixToPosCnv_CUR2, constant=HVAC_CRCHmixToPosCnv_CUR2}
          HVAC_CRCHmixToPosCnv_CUR3: type=Appl_HVAC_CRCHmixToPosCnv_CUR3, init-value=constant-reference={short-label=HVAC_CRCHmixToPosCnv_CUR3, constant=HVAC_CRCHmixToPosCnv_CUR3}
          HVAC_CRCPosToHmixCnv_CUR: type=Appl_HVAC_CRCPosToHmixCnv_CUR, init-value=constant-reference={short-label=HVAC_CRCPosToHmixCnv_CUR, constant=HVAC_CRCPosToHmixCnv_CUR}
          HVAC_CRCPosToHmixCnv_CUR2: type=Appl_HVAC_CRCPosToHmixCnv_CUR2, init-value=constant-reference={short-label=HVAC_CRCPosToHmixCnv_CUR2, constant=HVAC_CRCPosToHmixCnv_CUR2}
          HVAC_CRCPosToHmixCnv_CUR3: type=Appl_HVAC_CRCPosToHmixCnv_CUR3, init-value=constant-reference={short-label=HVAC_CRCPosToHmixCnv_CUR3, constant=HVAC_CRCPosToHmixCnv_CUR3}
          HVAC_DrTempHmixToPosCnv_CUR: type=Appl_HVAC_DrTempHmixToPosCnv_CUR, init-value=constant-reference={short-label=HVAC_DrTempHmixToPosCnv_CUR, constant=HVAC_DrTempHmixToPosCnv_CUR}
          HVAC_DrTempHmixToPosCnv_CUR2: type=Appl_HVAC_DrTempHmixToPosCnv_CUR2, init-value=constant-reference={short-label=HVAC_DrTempHmixToPosCnv_CUR2, constant=HVAC_DrTempHmixToPosCnv_CUR2}
          HVAC_DrTempHmixToPosCnv_CUR3: type=Appl_HVAC_DrTempHmixToPosCnv_CUR3, init-value=constant-reference={short-label=HVAC_DrTempHmixToPosCnv_CUR3, constant=HVAC_DrTempHmixToPosCnv_CUR3}
          HVAC_DrTempPosToHmixCnv_CUR: type=Appl_HVAC_DrTempPosToHmixCnv_CUR, init-value=constant-reference={short-label=HVAC_DrTempPosToHmixCnv_CUR, constant=HVAC_DrTempPosToHmixCnv_CUR}
          HVAC_DrTempPosToHmixCnv_CUR2: type=Appl_HVAC_DrTempPosToHmixCnv_CUR2, init-value=constant-reference={short-label=HVAC_DrTempPosToHmixCnv_CUR2, constant=HVAC_DrTempPosToHmixCnv_CUR2}
          HVAC_DrTempPosToHmixCnv_CUR3: type=Appl_HVAC_DrTempPosToHmixCnv_CUR3, init-value=constant-reference={short-label=HVAC_DrTempPosToHmixCnv_CUR3, constant=HVAC_DrTempPosToHmixCnv_CUR3}
          HVAC_PaTempHmixToPosCnv_CUR: type=Appl_HVAC_PaTempHmixToPosCnv_CUR, init-value=constant-reference={short-label=HVAC_PaTempHmixToPosCnv_CUR, constant=HVAC_PaTempHmixToPosCnv_CUR}
          HVAC_PaTempHmixToPosCnv_CUR2: type=Appl_HVAC_PaTempHmixToPosCnv_CUR2, init-value=constant-reference={short-label=HVAC_PaTempHmixToPosCnv_CUR2, constant=HVAC_PaTempHmixToPosCnv_CUR2}
          HVAC_PaTempHmixToPosCnv_CUR3: type=Appl_HVAC_PaTempHmixToPosCnv_CUR3, init-value=constant-reference={short-label=HVAC_PaTempHmixToPosCnv_CUR3, constant=HVAC_PaTempHmixToPosCnv_CUR3}
          HVAC_PaTempPosToHmixCnv_CUR: type=Appl_HVAC_PaTempPosToHmixCnv_CUR, init-value=constant-reference={short-label=HVAC_PaTempPosToHmixCnv_CUR, constant=HVAC_PaTempPosToHmixCnv_CUR}
          HVAC_PaTempPosToHmixCnv_CUR2: type=Appl_HVAC_PaTempPosToHmixCnv_CUR2, init-value=constant-reference={short-label=HVAC_PaTempPosToHmixCnv_CUR2, constant=HVAC_PaTempPosToHmixCnv_CUR2}
          HVAC_PaTempPosToHmixCnv_CUR3: type=Appl_HVAC_PaTempPosToHmixCnv_CUR3, init-value=constant-reference={short-label=HVAC_PaTempPosToHmixCnv_CUR3, constant=HVAC_PaTempPosToHmixCnv_CUR3}
          HvacDampr_ReTempHmixToPosCnv_CUR: type=Appl_HvacDampr_ReTempHmixToPosCnv_CUR, init-value=constant-reference=HvacDampr_ReTempHmixToPosCnv_CUR
          HvacDampr_ReTempHmixToPosCnv2_CUR: type=Appl_HvacDampr_ReTempHmixToPosCnv2_CUR, init-value=constant-reference=HvacDampr_ReTempHmixToPosCnv2_CUR
          HvacDampr_ReTempHmixToPosCnv3_CUR: type=Appl_HvacDampr_ReTempHmixToPosCnv3_CUR, init-value=constant-reference=HvacDampr_ReTempHmixToPosCnv3_CUR
          HvacDampr_ReTempPosToHmixCnv_CUR: type=Appl_HvacDampr_ReTempPosToHmixCnv_CUR, init-value=constant-reference=HvacDampr_ReTempPosToHmixCnv_CUR
          HvacDampr_ReTempPosToHmixCnv2_CUR: type=Appl_HvacDampr_ReTempPosToHmixCnv2_CUR, init-value=constant-reference=HvacDampr_ReTempPosToHmixCnv2_CUR
          HvacDampr_ReTempPosToHmixCnv3_CUR: type=Appl_HvacDampr_ReTempPosToHmixCnv3_CUR, init-value=constant-reference=HvacDampr_ReTempPosToHmixCnv3_CUR
          MDD_CRC_2LAYER_FLOW_SPEC_1: type=ImplementationDataTypes/uint16, init-value=constant-reference={short-label=MDD_CRC_2LAYER_FLOW_SPEC_1, constant=MDD_CRC_2LAYER_FLOW_SPEC_1}
          MDD_CRC_2LAYER_FLOW_SPEC_2: type=ImplementationDataTypes/uint16, init-value=constant-reference={short-label=MDD_CRC_2LAYER_FLOW_SPEC_2, constant=MDD_CRC_2LAYER_FLOW_SPEC_2}
          MDD_DEF_POSITION_SPEC_{1..3}: type=ImplementationDataTypes/uint16, init-value=constant-reference={short-label=MDD_DEF_POSITION_SPEC_{1..3}, constant=MDD_DEF_POSITION_SPEC_{1..3}}
          MDD_FLR_POSITION_SPEC_{1..3}: type=ImplementationDataTypes/uint16, init-value=constant-reference={short-label=MDD_FLR_POSITION_SPEC_{1..3}, constant=MDD_FLR_POSITION_SPEC_{1..3}}
          MDD_FLRDEF_POSITION_SPEC_{1..3}: type=ImplementationDataTypes/uint16, init-value=constant-reference={short-label=MDD_FLRDEF_POSITION_SPEC_{1..3}, constant=MDD_FLRDEF_POSITION_SPEC_{1..3}}
          MDD_PNL_POSITION_SPEC_{1..3}: type=ImplementationDataTypes/uint16, init-value=constant-reference={short-label=MDD_PNL_POSITION_SPEC_{1..3}, constant=MDD_PNL_POSITION_SPEC_{1..3}}
          MDD_PNL_VAL: type=ImplementationDataTypes/uint8, init-value=constant-reference={short-label=MDD_PNL_VAL, constant=MDD_PNL_VAL}
          MDD_PNLFLR_POSITION_SPEC_{1..3}: type=ImplementationDataTypes/uint16, init-value=constant-reference={short-label=MDD_PNLFLR_POSITION_SPEC_{1..3}, constant=MDD_PNLFLR_POSITION_SPEC_{1..3}}
          MDD_PNLFLR_POSITION_SPEC_4: type=ImplementationDataTypes/uint16, init-value=constant-reference={short-label=MDD_PNLFLR_POSITION_SPEC_3, constant=MDD_PNLFLR_POSITION_SPEC_3}
          MDD_RE_FLR_POSITION_SPEC_1: type=ImplementationDataTypes/uint16, init-value=constant-reference=MDD_RE_FLR_POSITION_SPEC_1
          MDD_RE_PNL_POSITION_SPEC_1: type=ImplementationDataTypes/uint16, init-value=constant-reference=MDD_RE_PNL_POSITION_SPEC_1
          MDD_RE_PNLFLR_POSITION_SPEC_1: type=ImplementationDataTypes/uint16, init-value=constant-reference=MDD_RE_PNLFLR_POSITION_SPEC_1
          MDD_RE_ST1_POSITION_SPEC_1: type=ImplementationDataTypes/uint16, init-value=constant-reference=MDD_RE_ST1_POSITION_SPEC_1
          MDD_RE_ST1_VAL_SPEC1: type=ImplementationDataTypes/uint8, init-value=constant-reference={short-label=MOTO_MODE_SPECT2_P_TURN, constant=MDD_RE_ST1_VAL_SPEC1}
          MDD_RE_ST2_POSITION_SPEC_1: type=ImplementationDataTypes/uint16, init-value=constant-reference=MDD_RE_ST2_POSITION_SPEC_1
          MDD_RE_ST2_VAL_SPEC1: type=ImplementationDataTypes/uint8, init-value=constant-reference={short-label=MOTO_MODE_SPECT2_P_TURN, constant=MDD_RE_ST2_VAL_SPEC1}
          MDD_RE_ST3_POSITION_SPEC_1: type=ImplementationDataTypes/uint16, init-value=constant-reference=MDD_RE_ST3_POSITION_SPEC_1
          MDD_RE_ST3_VAL_SPEC1: type=ImplementationDataTypes/uint8, init-value=constant-reference={short-label=MOTO_MODE_SPECT2_P_TURN, constant=MDD_RE_ST3_VAL_SPEC1}
          MDD_ST_RE_DIFF_POSITION: type=ImplementationDataTypes/uint16, init-value=constant-reference={short-label=MDD_ST_RE_DIFF_POSITION, constant=MDD_ST_RE_DIFF_POSITION}
          MDD_ST1_POSITION_SPEC_{1..3}: type=ImplementationDataTypes/uint16, init-value=constant-reference={short-label=MDD_ST1_POSITION_SPEC_{1..3}, constant=MDD_ST1_POSITION_SPEC_{1..3}}
          MDD_ST1_VAL_SPEC{1..3}: type=ImplementationDataTypes/uint8, init-value=constant-reference={short-label=MDD_ST1_VAL_SPEC{1..3}, constant=MDD_ST1_VAL_SPEC{1..3}}
          MDD_ST2_POSITION_SPEC_{1..3}: type=ImplementationDataTypes/uint16, init-value=constant-reference={short-label=MDD_ST2_POSITION_SPEC_{1..3}, constant=MDD_ST2_POSITION_SPEC_{1..3}}
          MDD_ST2_VAL_SPEC{1..3}: type=ImplementationDataTypes/uint8, init-value=constant-reference={short-label=MDD_ST2_VAL_SPEC{1..3}, constant=MDD_ST2_VAL_SPEC{1..3}}
          MDD_ST3_POSITION_SPEC_{1..3}: type=ImplementationDataTypes/uint16, init-value=constant-reference={short-label=MDD_ST3_POSITION_SPEC_{1..3}, constant=MDD_ST3_POSITION_SPEC_{1..3}}
          MDD_ST3_VAL_SPEC{1..3}: type=ImplementationDataTypes/uint8, init-value=constant-reference={short-label=MDD_ST3_VAL_SPEC{1..3}, constant=MDD_ST3_VAL_SPEC{1..3}}
          MDD_ST4_POSITION_SPEC_{1..3}: type=ImplementationDataTypes/uint16, init-value=constant-reference={short-label=MDD_ST4_POSITION_SPEC_{1..3}, constant=MDD_ST4_POSITION_SPEC_{1..3}}
          MDD_ST4_VAL_SPEC{1..3}: type=ImplementationDataTypes/uint8, init-value=constant-reference={short-label=MDD_ST4_VAL_SPEC{1..3}, constant=MDD_ST4_VAL_SPEC{1..3}}
          MDD_ST5_POSITION_SPEC_{1..3}: type=ImplementationDataTypes/uint16, init-value=constant-reference={short-label=MDD_ST5_POSITION_SPEC_{1..3}, constant=MDD_ST5_POSITION_SPEC_{1..3}}
          MDD_ST5_VAL_SPEC{1..3}: type=ImplementationDataTypes/uint8, init-value=constant-reference={short-label=MDD_ST5_VAL_SPEC{1..3}, constant=MDD_ST5_VAL_SPEC{1..3}}
          MOTO_CRC_SPECT1_P_TURN: type=ImplementationDataTypes/uint8, init-value=constant-reference={short-label=MOTO_CRC_SPECT1_P_TURN, constant=MOTO_CRC_SPECT1_P_TURN}
          MOTO_CRC_SPECT1_R_TURN: type=ImplementationDataTypes/uint8, init-value=constant-reference={short-label=MOTO_CRC_SPECT1_R_TURN, constant=MOTO_CRC_SPECT1_R_TURN}
          MOTO_CRC_SPECT2_P_TURN: type=ImplementationDataTypes/uint8, init-value=constant-reference={short-label=MOTO_CRC_SPECT2_P_TURN, constant=MOTO_CRC_SPECT2_P_TURN}
          MOTO_CRC_SPECT2_R_TURN: type=ImplementationDataTypes/uint8, init-value=constant-reference={short-label=MOTO_CRC_SPECT2_R_TURN, constant=MOTO_CRC_SPECT2_R_TURN}
          MOTO_CRC_SPECT3_P_TURN: type=ImplementationDataTypes/uint8, init-value=constant-reference={short-label=MOTO_CRC_SPECT3_P_TURN, constant=MOTO_CRC_SPECT3_P_TURN}
          MOTO_CRC_SPECT3_R_TURN: type=ImplementationDataTypes/uint8, init-value=constant-reference={short-label=MOTO_CRC_SPECT3_R_TURN, constant=MOTO_CRC_SPECT3_R_TURN}
          MOTO_DR_TEMP_SPECT1_P_TURN: type=ImplementationDataTypes/uint8, init-value=constant-reference={short-label=MOTO_DR_TEMP_SPECT1_P_TURN, constant=MOTO_DR_TEMP_SPECT1_P_TURN}
          MOTO_DR_TEMP_SPECT1_R_TURN: type=ImplementationDataTypes/uint8, init-value=constant-reference={short-label=MOTO_DR_TEMP_SPECT1_R_TURN, constant=MOTO_DR_TEMP_SPECT1_R_TURN}
          MOTO_DR_TEMP_SPECT2_P_TURN: type=ImplementationDataTypes/uint8, init-value=constant-reference={short-label=MOTO_DR_TEMP_SPECT2_P_TURN, constant=MOTO_DR_TEMP_SPECT2_P_TURN}
          MOTO_DR_TEMP_SPECT2_R_TURN: type=ImplementationDataTypes/uint8, init-value=constant-reference={short-label=MOTO_DR_TEMP_SPECT2_R_TURN, constant=MOTO_DR_TEMP_SPECT2_R_TURN}
          MOTO_DR_TEMP_SPECT3_P_TURN: type=ImplementationDataTypes/uint8, init-value=constant-reference={short-label=MOTO_DR_TEMP_SPECT3_P_TURN, constant=MOTO_DR_TEMP_SPECT3_P_TURN}
          MOTO_DR_TEMP_SPECT3_R_TURN: type=ImplementationDataTypes/uint8, init-value=constant-reference={short-label=MOTO_DR_TEMP_SPECT3_R_TURN, constant=MOTO_DR_TEMP_SPECT3_R_TURN}
          MOTO_FALSE_JUDGE_VAL: type=ImplementationDataTypes/uint16, init-value=constant-reference={short-label=MOTO_FALSE_JUDGE_VAL, constant=MOTO_FALSE_JUDGE_VAL}
          MOTO_INIT_DEAL_TIME: type=ImplementationDataTypes/uint8, init-value=constant-reference={short-label=MOTO_INIT_DEAL_TIME, constant=MOTO_INIT_DEAL_TIME}
          MOTO_MODE_SPECT1_P_TURN: type=ImplementationDataTypes/uint8, init-value=constant-reference={short-label=MOTO_MODE_SPECT1_P_TURN, constant=MOTO_MODE_SPECT1_P_TURN}
          MOTO_MODE_SPECT1_R_TURN: type=ImplementationDataTypes/uint8, init-value=constant-reference={short-label=MOTO_MODE_SPECT1_R_TURN, constant=MOTO_MODE_SPECT1_R_TURN}
          MOTO_MODE_SPECT2_P_TURN: type=ImplementationDataTypes/uint8, init-value=constant-reference={short-label=MOTO_MODE_SPECT2_P_TURN, constant=MOTO_MODE_SPECT2_P_TURN}
          MOTO_MODE_SPECT2_R_TURN: type=ImplementationDataTypes/uint8, init-value=constant-reference={short-label=MOTO_MODE_SPECT2_R_TURN, constant=MOTO_MODE_SPECT2_R_TURN}
          MOTO_MODE_SPECT3_P_TURN: type=ImplementationDataTypes/uint8, init-value=constant-reference={short-label=MOTO_MODE_SPECT3_P_TURN, constant=MOTO_MODE_SPECT3_P_TURN}
          MOTO_MODE_SPECT3_R_TURN: type=ImplementationDataTypes/uint8, init-value=constant-reference={short-label=MOTO_MODE_SPECT3_R_TURN, constant=MOTO_MODE_SPECT3_R_TURN}
          MOTO_PA_TEMP_SPECT1_P_TURN: type=ImplementationDataTypes/uint8, init-value=constant-reference={short-label=MOTO_PA_TEMP_SPECT1_P_TURN, constant=MOTO_PA_TEMP_SPECT1_P_TURN}
          MOTO_PA_TEMP_SPECT1_R_TURN: type=ImplementationDataTypes/uint8, init-value=constant-reference={short-label=MOTO_PA_TEMP_SPECT1_R_TURN, constant=MOTO_PA_TEMP_SPECT1_R_TURN}
          MOTO_PA_TEMP_SPECT2_P_TURN: type=ImplementationDataTypes/uint8, init-value=constant-reference={short-label=MOTO_PA_TEMP_SPECT2_P_TURN, constant=MOTO_PA_TEMP_SPECT2_P_TURN}
          MOTO_PA_TEMP_SPECT2_R_TURN: type=ImplementationDataTypes/uint8, init-value=constant-reference={short-label=MOTO_PA_TEMP_SPECT2_R_TURN, constant=MOTO_PA_TEMP_SPECT2_R_TURN}
          MOTO_PA_TEMP_SPECT3_P_TURN: type=ImplementationDataTypes/uint8, init-value=constant-reference={short-label=MOTO_PA_TEMP_SPECT3_P_TURN, constant=MOTO_PA_TEMP_SPECT3_P_TURN}
          MOTO_PA_TEMP_SPECT3_R_TURN: type=ImplementationDataTypes/uint8, init-value=constant-reference={short-label=MOTO_PA_TEMP_SPECT3_R_TURN, constant=MOTO_PA_TEMP_SPECT3_R_TURN}
          MOTO_RE_TEMP_SPECT1_P_TURN: type=ImplementationDataTypes/uint8, init-value=constant-reference={short-label=MOTO_PA_TEMP_SPECT1_P_TURN, constant=MOTO_RE_TEMP_SPECT1_P_TURN}
          MOTO_RE_TEMP_SPECT1_R_TURN: type=ImplementationDataTypes/uint8, init-value=constant-reference={short-label=MOTO_PA_TEMP_SPECT1_R_TURN, constant=MOTO_RE_TEMP_SPECT1_R_TURN}
          MOTO_RE_TEMP_SPECT2_P_TURN: type=ImplementationDataTypes/uint8, init-value=constant-reference={short-label=MOTO_PA_TEMP_SPECT2_P_TURN, constant=MOTO_RE_TEMP_SPECT2_P_TURN}
          MOTO_RE_TEMP_SPECT2_R_TURN: type=ImplementationDataTypes/uint8, init-value=constant-reference={short-label=MOTO_PA_TEMP_SPECT2_R_TURN, constant=MOTO_RE_TEMP_SPECT2_R_TURN}
          MOTO_RE_TEMP_SPECT3_P_TURN: type=ImplementationDataTypes/uint8, init-value=constant-reference={short-label=MOTO_PA_TEMP_SPECT3_P_TURN, constant=MOTO_RE_TEMP_SPECT3_P_TURN}
          MOTO_RE_TEMP_SPECT3_R_TURN: type=ImplementationDataTypes/uint8, init-value=constant-reference={short-label=MOTO_PA_TEMP_SPECT3_R_TURN, constant=MOTO_RE_TEMP_SPECT3_R_TURN}
          MOTO_REMODE_SPECT1_P_TURN: type=ImplementationDataTypes/uint8, init-value=constant-reference={short-label=MOTO_MODE_SPECT2_R_TURN, constant=MOTO_REMODE_SPECT1_P_TURN}
          MOTO_REMODE_SPECT1_R_TURN: type=ImplementationDataTypes/uint8, init-value=constant-reference={short-label=MOTO_MODE_SPECT2_P_TURN, constant=MOTO_REMODE_SPECT1_R_TURN}
          MOTO_RUNNING: type=ImplementationDataTypes/boolean, init-value=constant-reference={short-label=MOTO_RUNNING, constant=MOTO_RUNNING}
          MOTO_STOP: type=ImplementationDataTypes/uint8, init-value=constant-reference={short-label=MOTO_STOP, constant=MOTO_STOP}
          MOTO_STOP_RUNNING: type=ImplementationDataTypes/boolean, init-value=constant-reference={short-label=MOTO_STOP_RUNNING, constant=MOTO_STOP_RUNNING}
          PRM_A02_CFG_SPEC_VAL: type=ImplementationDataTypes/uint8, init-value=constant-reference={short-label=PRM_A02_CFG_SPEC_VAL, constant=PRM_A02_CFG_SPEC_VAL}
          PRM_A08_CFG_SPEC_VAL: type=ImplementationDataTypes/uint8, init-value=constant-reference={short-label=PRM_A08_CFG_SPEC_VAL, constant=PRM_A08_CFG_SPEC_VAL}
          PRM_A29_CFG_SPEC_VAL: type=ImplementationDataTypes/uint8, init-value=constant-reference={short-label=PRM_A29_CFG_SPEC_VAL, constant=PRM_A29_CFG_SPEC_VAL}
package /UAES/ASW/Units
  unit mV: display-name=mV, factor-si-to-unit=1, offset-si-to-unit=0
  unit NoUnit: factor-si-to-unit=1, offset-si-to-unit=0
